VERSION ""

NS_ :

BS_:

BU_: AVM SCC ACU BCW ECS CLU ESC CGW RVM EPB SAS AFS MDPS FR_CMR FR_RDR HUD
VAL_TABLE_ CF_AVN_WarningTimingNValueSet 7 "Invliad" 6 "Reserved" 5 "Reserved" 4 "Reserved" 3 "Reserved" 2 "Normal" 1 "Late" 0 "Default" ;

BO_ 3221225472 VECTOR__INDEPENDENT_SIG_MSG: 0 Vector__XXX
 SG_ ISLA_OptUsmSta : 0|8@1+ (1,0) [0|255] "" Vector__XXX
 SG_ FRM_FORMAT : 0|8@1+ (1,0) [0|31] "" Vector__XXX
 SG_ SID : 0|8@1+ (1,0) [0|255] "" Vector__XXX
 SG_ REQ_RESPONSE : 0|8@1+ (1,0) [0|2] "" Vector__XXX

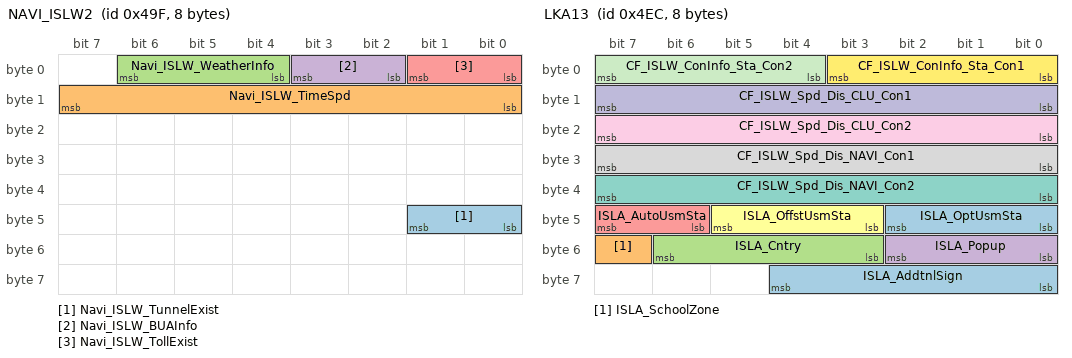
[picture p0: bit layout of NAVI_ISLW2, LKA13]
BO_ 1183 NAVI_ISLW2: 8 CGW
 SG_ Navi_ISLW_TunnelExist : 40|2@1+ (1,0) [0|3] ""  FR_CMR
 SG_ Navi_ISLW_TimeSpd : 8|8@1+ (1,0) [0|255] ""  FR_CMR
 SG_ Navi_ISLW_WeatherInfo : 4|3@1+ (1,0) [0|7] ""  FR_CMR
 SG_ Navi_ISLW_BUAInfo : 2|2@1+ (1,0) [0|3] ""  FR_CMR
 SG_ Navi_ISLW_TollExist : 0|2@1+ (1,0) [0|3] ""  FR_CMR

BO_ 1260 LKA13: 8 FR_CMR
 SG_ ISLA_AddtnlSign : 56|5@1+ (1,0) [0|31] ""  CLU,CGW
 SG_ ISLA_SchoolZone : 55|1@1+ (1,0) [0|1] ""  CLU,CGW
 SG_ ISLA_Cntry : 51|4@1+ (1,0) [0|15] ""  CLU,CGW
 SG_ ISLA_Popup : 48|3@1+ (1,0) [0|7] ""  CLU,CGW
 SG_ ISLA_AutoUsmSta : 46|2@1+ (1,0) [0|3] ""  CLU,CGW
 SG_ ISLA_OffstUsmSta : 43|3@1+ (1,0) [0|7] ""  CLU,CGW
 SG_ CF_ISLW_Spd_Dis_NAVI_Con2 : 32|8@1+ (1,0) [0|255] "" Vector__XXX
 SG_ CF_ISLW_Spd_Dis_NAVI_Con1 : 24|8@1+ (1,0) [-128|127] ""  CGW
 SG_ CF_ISLW_Spd_Dis_CLU_Con2 : 16|8@1+ (1,0) [0|255] "" Vector__XXX
 SG_ CF_ISLW_Spd_Dis_CLU_Con1 : 8|8@1+ (1,0) [0|255] ""  CLU,CGW
 SG_ CF_ISLW_ConInfo_Sta_Con2 : 4|4@1+ (1,0) [0|15] ""  CLU,CGW
 SG_ CF_ISLW_ConInfo_Sta_Con1 : 0|4@1+ (1,0) [0|15] ""  CGW,CLU
 SG_ ISLA_OptUsmSta : 40|3@1+ (1,0) [0|7] ""  SCC,CLU,CGW

BO_ 2679898134 MEAS_5: 8 FR_CMR
 SG_ Meas5Data : 0|64@1+ (1,0) [0|1.84467440737096E+019] "" Vector__XXX

BO_ 2679898133 MEAS_4: 8 FR_CMR
 SG_ Meas4Data : 0|64@1+ (1,0) [0|1.84467440737096E+019] "" Vector__XXX

BO_ 2679898132 MEAS_3: 8 FR_CMR
 SG_ Meas3Data : 0|64@1+ (1,0) [0|1.84467440737096E+019] "" Vector__XXX

BO_ 2679898131 MEAS_2: 8 FR_CMR
 SG_ Meas2Data : 0|64@1+ (1,0) [0|1.84467440737096E+019] "" Vector__XXX

BO_ 2679898130 MEAS_1: 8 FR_CMR
 SG_ Meas1Data : 0|64@1+ (1,0) [0|0] "" Vector__XXX

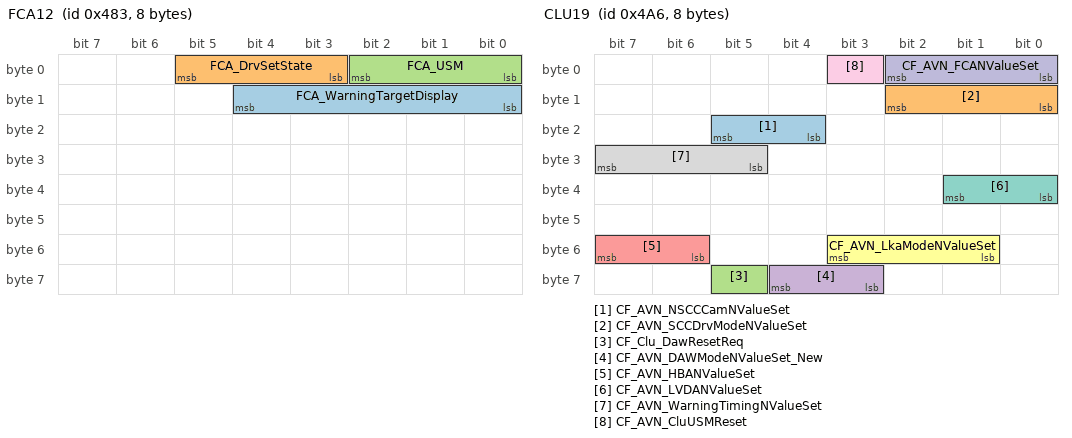
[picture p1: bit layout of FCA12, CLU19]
BO_ 1155 FCA12: 8 FR_CMR
 SG_ FCA_WarningTargetDisplay : 8|5@1+ (1,0) [0|31] ""  CLU
 SG_ FCA_DrvSetState : 3|3@1+ (1,0) [0|7] ""  FR_CMR,CLU
 SG_ FCA_USM : 0|3@1+ (1,0) [0|7] ""  ESC,CLU

BO_ 1190 CLU19: 8 CLU
 SG_ CF_AVN_NSCCCamNValueSet : 20|2@1+ (1,0) [0|3] ""  SCC,FR_CMR
 SG_ CF_AVN_SCCDrvModeNValueSet : 8|3@1+ (1,0) [0|7] ""  SCC,FR_CMR
 SG_ CF_Clu_DawResetReq : 61|1@1+ (1,0) [0|1] ""  FR_CMR
 SG_ CF_AVN_DAWModeNValueSet_New : 59|2@1+ (1,0) [0|3] "" Vector__XXX
 SG_ CF_AVN_HBANValueSet : 54|2@1+ (1,0) [0|3] ""  FR_CMR
 SG_ CF_AVN_LkaModeNValueSet : 49|3@1+ (1,0) [0|7] ""  FR_CMR
 SG_ CF_AVN_LVDANValueSet : 32|2@1+ (1,0) [0|3] ""  FR_CMR
 SG_ CF_AVN_WarningTimingNValueSet : 29|3@1+ (1,0) [0|7] ""  FR_CMR
 SG_ CF_AVN_CluUSMReset : 3|1@1+ (1,0) [0|1] ""  FR_CMR
 SG_ CF_AVN_FCANValueSet : 0|3@1+ (1,0) [0|7] ""  FR_CMR

BO_ 1729 XCP_Tx_Pdu: 8 FR_CMR
 SG_ XCP_Tx_Data : 0|64@1+ (1,0) [0|1.84467440737096E+019] "" Vector__XXX

BO_ 1728 XCP_Rx_Pdu: 8 Vector__XXX
 SG_ XCP_Rx_Data : 0|64@1+ (1,0) [0|1.84467440737096E+019] ""  FR_CMR

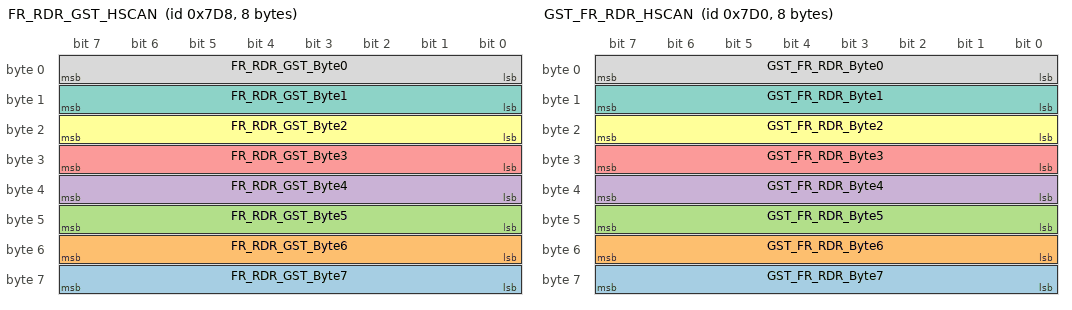
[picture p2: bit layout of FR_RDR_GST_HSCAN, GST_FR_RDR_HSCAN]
BO_ 2008 FR_RDR_GST_HSCAN: 8 FR_CMR
 SG_ FR_RDR_GST_Byte7 : 56|8@1+ (1,0) [0|255] ""  CGW
 SG_ FR_RDR_GST_Byte6 : 48|8@1+ (1,0) [0|255] ""  CGW
 SG_ FR_RDR_GST_Byte5 : 40|8@1+ (1,0) [0|255] ""  CGW
 SG_ FR_RDR_GST_Byte4 : 32|8@1+ (1,0) [0|255] ""  CGW
 SG_ FR_RDR_GST_Byte3 : 24|8@1+ (1,0) [0|255] ""  CGW
 SG_ FR_RDR_GST_Byte2 : 16|8@1+ (1,0) [0|255] ""  CGW
 SG_ FR_RDR_GST_Byte1 : 8|8@1+ (1,0) [0|255] ""  CGW
 SG_ FR_RDR_GST_Byte0 : 0|8@1+ (1,0) [0|255] ""  CGW

BO_ 2000 GST_FR_RDR_HSCAN: 8 CGW
 SG_ GST_FR_RDR_Byte7 : 56|8@1+ (1,0) [0|255] ""  FR_CMR
 SG_ GST_FR_RDR_Byte6 : 48|8@1+ (1,0) [0|255] ""  FR_CMR
 SG_ GST_FR_RDR_Byte5 : 40|8@1+ (1,0) [0|255] ""  FR_CMR
 SG_ GST_FR_RDR_Byte4 : 32|8@1+ (1,0) [0|255] ""  FR_CMR
 SG_ GST_FR_RDR_Byte3 : 24|8@1+ (1,0) [0|255] ""  FR_CMR
 SG_ GST_FR_RDR_Byte2 : 16|8@1+ (1,0) [0|255] ""  FR_CMR
 SG_ GST_FR_RDR_Byte1 : 8|8@1+ (1,0) [0|255] ""  FR_CMR
 SG_ GST_FR_RDR_Byte0 : 0|8@1+ (1,0) [0|255] ""  FR_CMR

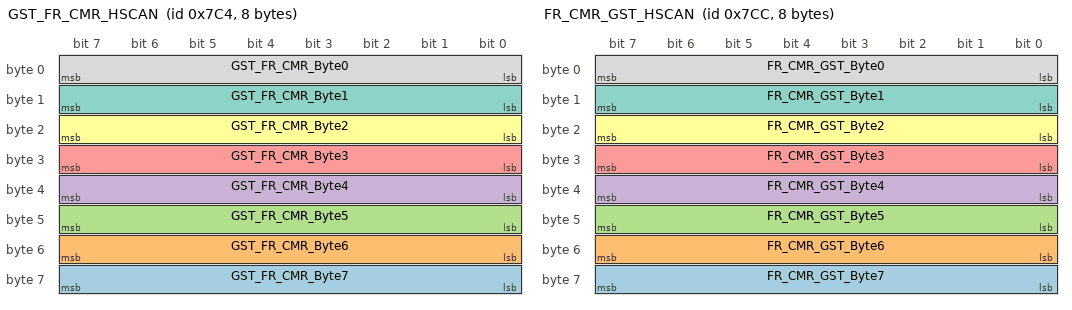
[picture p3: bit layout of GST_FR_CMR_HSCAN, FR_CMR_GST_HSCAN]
BO_ 1988 GST_FR_CMR_HSCAN: 8 CGW
 SG_ GST_FR_CMR_Byte7 : 56|8@1+ (1,0) [0|255] ""  FR_CMR
 SG_ GST_FR_CMR_Byte6 : 48|8@1+ (1,0) [0|255] ""  FR_CMR
 SG_ GST_FR_CMR_Byte5 : 40|8@1+ (1,0) [0|255] ""  FR_CMR
 SG_ GST_FR_CMR_Byte4 : 32|8@1+ (1,0) [0|255] ""  FR_CMR
 SG_ GST_FR_CMR_Byte3 : 24|8@1+ (1,0) [0|255] ""  FR_CMR
 SG_ GST_FR_CMR_Byte2 : 16|8@1+ (1,0) [0|255] ""  FR_CMR
 SG_ GST_FR_CMR_Byte1 : 8|8@1+ (1,0) [0|255] ""  FR_CMR
 SG_ GST_FR_CMR_Byte0 : 0|8@1+ (1,0) [0|255] ""  FR_CMR

BO_ 1996 FR_CMR_GST_HSCAN: 8 FR_CMR
 SG_ FR_CMR_GST_Byte7 : 56|8@1+ (1,0) [0|255] ""  CGW
 SG_ FR_CMR_GST_Byte6 : 48|8@1+ (1,0) [0|255] ""  CGW
 SG_ FR_CMR_GST_Byte5 : 40|8@1+ (1,0) [0|255] ""  CGW
 SG_ FR_CMR_GST_Byte4 : 32|8@1+ (1,0) [0|255] ""  CGW
 SG_ FR_CMR_GST_Byte3 : 24|8@1+ (1,0) [0|255] ""  CGW
 SG_ FR_CMR_GST_Byte2 : 16|8@1+ (1,0) [0|255] ""  CGW
 SG_ FR_CMR_GST_Byte1 : 8|8@1+ (1,0) [0|255] ""  CGW
 SG_ FR_CMR_GST_Byte0 : 0|8@1+ (1,0) [0|255] ""  CGW

BO_ 550 NAVI_STD_STUB_E: 8 CGW
 SG_ STUB_MessageType : 0|3@1+ (1,0) [0|7] ""  FR_CMR,SCC
 SG_ STUB_Offset : 3|13@1+ (1,0) [0|8191] ""  FR_CMR,SCC
 SG_ STUB_CyclicCounter : 16|2@1+ (1,0) [0|3] ""  FR_CMR,SCC
 SG_ STUB_PathIndex : 18|6@1+ (1,0) [0|63] ""  FR_CMR,SCC
 SG_ STUB_SubPathIndex : 24|6@1+ (1,0) [0|63] ""  FR_CMR,SCC
 SG_ STUB_Retransmission : 30|1@1+ (1,0) [0|1] ""  FR_CMR,SCC
 SG_ STUB_Update : 31|1@1+ (1,0) [0|1] ""  FR_CMR,SCC
 SG_ STUB_RelativeProbability : 32|5@1+ (3.333,0) [0|103.323] ""  FR_CMR,SCC
 SG_ STUB_FunctionalRoadClass : 37|3@1+ (1,0) [0|7] ""  FR_CMR,SCC
 SG_ STUB_CalculatedRoute : 40|2@1+ (1,0) [0|3] ""  FR_CMR,SCC
 SG_ STUB_ComplexIntersection : 42|2@1+ (1,0) [0|3] ""  FR_CMR,SCC
 SG_ STUB_FormOfWay : 44|4@1+ (1,0) [0|15] ""  FR_CMR,SCC
 SG_ STUB_TurnAngle : 48|8@1+ (1.417,0) [0|361.335] ""  FR_CMR,SCC
 SG_ STUB_LastStubAtOffset : 56|1@1+ (1,0) [0|1] ""  FR_CMR,SCC
 SG_ STUB_RightOfWay : 57|2@1+ (1,0) [0|3] ""  FR_CMR,SCC
 SG_ STUB_OppositeLanes : 59|2@1+ (1,0) [0|3] ""  FR_CMR,SCC
 SG_ STUB_DirectionLanes : 61|3@1+ (1,0) [0|7] ""  FR_CMR,SCC

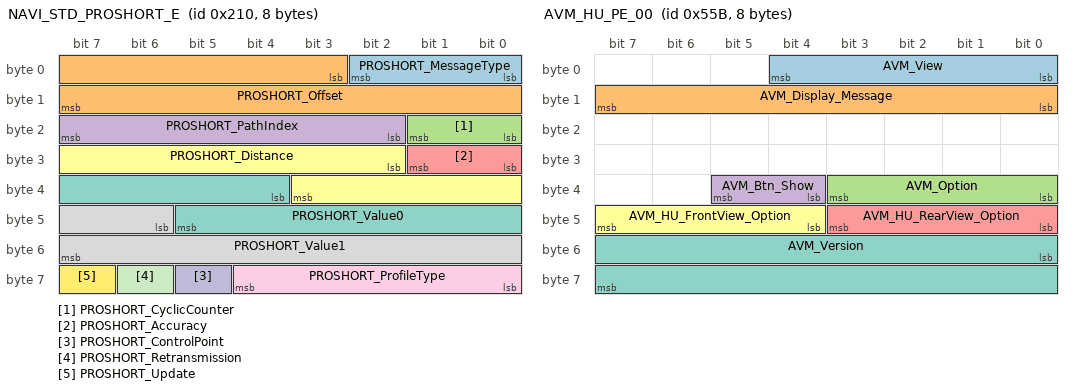
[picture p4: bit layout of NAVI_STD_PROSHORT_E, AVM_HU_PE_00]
BO_ 528 NAVI_STD_PROSHORT_E: 8 CGW
 SG_ PROSHORT_MessageType : 0|3@1+ (1,0) [0|7] ""  FR_CMR,SCC
 SG_ PROSHORT_Offset : 3|13@1+ (1,0) [0|8191] ""  FR_CMR,SCC
 SG_ PROSHORT_CyclicCounter : 16|2@1+ (1,0) [0|3] ""  FR_CMR,SCC
 SG_ PROSHORT_PathIndex : 18|6@1+ (1,0) [0|63] ""  FR_CMR,SCC
 SG_ PROSHORT_Accuracy : 24|2@1+ (1,0) [0|3] ""  FR_CMR,SCC
 SG_ PROSHORT_Distance : 26|10@1+ (1,0) [0|1023] ""  FR_CMR,SCC
 SG_ PROSHORT_Value0 : 36|10@1+ (1,0) [0|1023] ""  FR_CMR,SCC
 SG_ PROSHORT_Value1 : 46|10@1+ (1,0) [0|1023] ""  FR_CMR,SCC
 SG_ PROSHORT_ProfileType : 56|5@1+ (1,0) [0|31] ""  FR_CMR,SCC
 SG_ PROSHORT_ControlPoint : 61|1@1+ (1,0) [0|1] ""  FR_CMR,SCC
 SG_ PROSHORT_Retransmission : 62|1@1+ (1,0) [0|1] ""  FR_CMR,SCC
 SG_ PROSHORT_Update : 63|1@1+ (1,0) [0|1] ""  FR_CMR,SCC

BO_ 524 NAVI_STD_SEG_E: 8 CGW
 SG_ SEG_MessageType : 0|3@1+ (1,0) [0|7] ""  FR_CMR,SCC
 SG_ SEG_Offset : 3|13@1+ (1,0) [0|8191] ""  FR_CMR,SCC
 SG_ SEG_CyclicCounter : 16|2@1+ (1,0) [0|3] ""  FR_CMR,SCC
 SG_ SEG_PathIndex : 18|6@1+ (1,0) [0|63] ""  FR_CMR,SCC
 SG_ SEG_Tunnel : 24|2@1+ (1,0) [0|3] ""  FR_CMR,SCC
 SG_ SEG_Bridge : 26|2@1+ (1,0) [0|3] ""  FR_CMR,SCC
 SG_ SEG_BuiltUpArea : 28|2@1+ (1,0) [0|3] ""  FR_CMR,SCC
 SG_ SEG_Retransmission : 30|1@1+ (1,0) [0|1] ""  FR_CMR,SCC
 SG_ SEG_Update : 31|1@1+ (1,0) [0|1] ""  FR_CMR,SCC
 SG_ SEG_RelativeProbability : 32|5@1+ (3.333,0) [0|103.323] ""  FR_CMR,SCC
 SG_ SEG_FunctionalRoadClass : 37|3@1+ (1,0) [0|7] ""  FR_CMR,SCC
 SG_ SEG_CalculatedRoute : 40|2@1+ (1,0) [0|3] ""  FR_CMR,SCC
 SG_ SEG_ComplexIntersection : 42|2@1+ (1,0) [0|3] ""  FR_CMR,SCC
 SG_ SEG_FormOfWay : 44|4@1+ (1,0) [0|15] ""  FR_CMR,SCC
 SG_ SEG_SpeedLimit : 48|5@1+ (1,0) [0|31] ""  FR_CMR,SCC
 SG_ SEG_SpeedLimitType : 53|3@1+ (1,0) [0|7] ""  FR_CMR,SCC
 SG_ SEG_DividedRoad : 57|2@1+ (1,0) [0|3] ""  FR_CMR,SCC
 SG_ SEG_OppositeLanes : 59|2@1+ (1,0) [0|3] ""  FR_CMR,SCC
 SG_ SEG_DirectionLanes : 61|3@1+ (1,0) [0|7] ""  FR_CMR,SCC

BO_ 1371 AVM_HU_PE_00: 8 AVM
 SG_ AVM_View : 0|5@1+ (1,0) [0|31] ""  CGW
 SG_ AVM_Display_Message : 8|8@1+ (1,0) [0|255] ""  CGW
 SG_ AVM_Option : 32|4@1+ (1,0) [0|15] ""  CGW
 SG_ AVM_Btn_Show : 36|2@1+ (1,0) [0|3] "enum"  CGW
 SG_ AVM_HU_RearView_Option : 40|4@1+ (1,0) [0|15] ""  CGW
 SG_ AVM_HU_FrontView_Option : 44|4@1+ (1,0) [0|15] ""  CGW
 SG_ AVM_Version : 48|16@1+ (1,0) [0|65535] ""  CGW

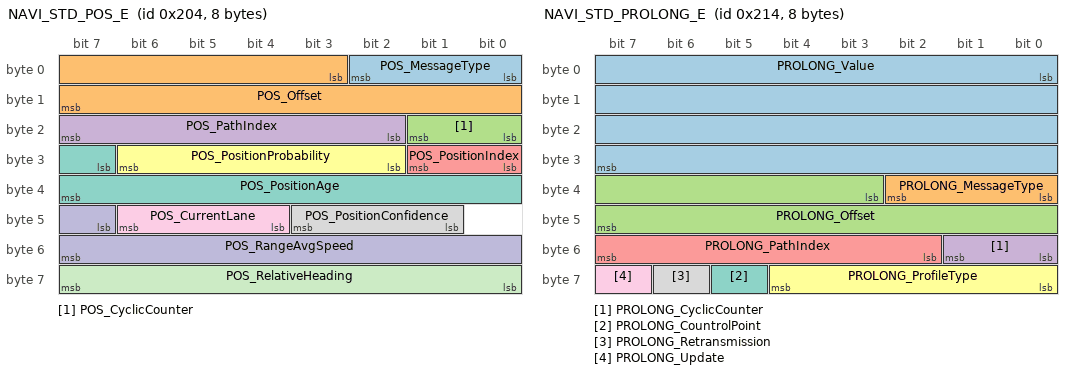
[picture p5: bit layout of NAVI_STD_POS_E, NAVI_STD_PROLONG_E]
BO_ 516 NAVI_STD_POS_E: 8 CGW
 SG_ POS_MessageType : 0|3@1+ (1,0) [0|7] ""  FR_CMR,SCC
 SG_ POS_Offset : 3|13@1+ (1,0) [0|8191] ""  FR_CMR,SCC
 SG_ POS_CyclicCounter : 16|2@1+ (1,0) [0|3] ""  FR_CMR,SCC
 SG_ POS_PathIndex : 18|6@1+ (1,0) [0|63] ""  FR_CMR,SCC
 SG_ POS_PositionIndex : 24|2@1+ (1,0) [0|3] ""  FR_CMR,SCC
 SG_ POS_PositionProbability : 26|5@1+ (3.333,0) [0|103.323] ""  FR_CMR,SCC
 SG_ POS_PositionAge : 31|9@1+ (5,0) [0|2555] ""  FR_CMR,SCC
 SG_ POS_PositionConfidence : 41|3@1+ (1,0) [0|7] ""  FR_CMR,SCC
 SG_ POS_CurrentLane : 44|3@1+ (1,0) [0|7] ""  FR_CMR,SCC
 SG_ POS_RangeAvgSpeed : 47|9@1+ (1,0) [0|511] ""  FR_CMR,SCC
 SG_ POS_RelativeHeading : 56|8@1+ (1.417,0) [0|361.335] ""  FR_CMR,SCC

BO_ 532 NAVI_STD_PROLONG_E: 8 CGW
 SG_ PROLONG_Value : 0|32@1+ (1,0) [0|4294967295] ""  FR_CMR,SCC
 SG_ PROLONG_MessageType : 32|3@1+ (1,0) [0|7] ""  FR_CMR,SCC
 SG_ PROLONG_Offset : 35|13@1+ (1,0) [0|8191] ""  FR_CMR,SCC
 SG_ PROLONG_CyclicCounter : 48|2@1+ (1,0) [0|3] ""  FR_CMR,SCC
 SG_ PROLONG_PathIndex : 50|6@1+ (1,0) [0|63] ""  FR_CMR,SCC
 SG_ PROLONG_ProfileType : 56|5@1+ (1,0) [0|31] ""  FR_CMR,SCC
 SG_ PROLONG_CountrolPoint : 61|1@1+ (1,0) [0|1] ""  FR_CMR,SCC
 SG_ PROLONG_Retransmission : 62|1@1+ (1,0) [0|1] ""  FR_CMR,SCC
 SG_ PROLONG_Update : 63|1@1+ (1,0) [0|1] ""  FR_CMR,SCC

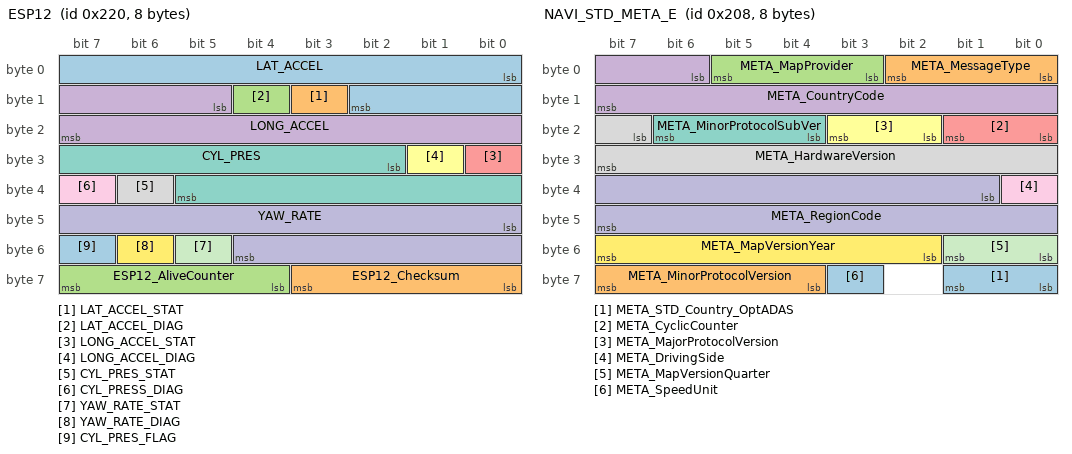
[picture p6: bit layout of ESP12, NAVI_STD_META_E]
BO_ 544 ESP12: 8 ESC
 SG_ LAT_ACCEL : 0|11@1+ (0.01,-10.23) [-10.23|10.24] "m/s^2"  CLU,ECS,FR_RDR,FR_CMR,SCC
 SG_ LAT_ACCEL_STAT : 11|1@1+ (1,0) [0|1] ""  CLU,ECS,FR_RDR,FR_CMR,SCC
 SG_ LAT_ACCEL_DIAG : 12|1@1+ (1,0) [0|1] ""  ECS,FR_RDR,FR_CMR,SCC
 SG_ LONG_ACCEL : 13|11@1+ (0.01,-10.23) [-10.23|10.24] "m/s^2"  CLU,EPB,FR_RDR,FR_CMR,SCC
 SG_ LONG_ACCEL_STAT : 24|1@1+ (1,0) [0|1] ""  CLU,EPB,FR_RDR,FR_CMR,SCC
 SG_ LONG_ACCEL_DIAG : 25|1@1+ (1,0) [0|1] ""  EPB,FR_RDR,FR_CMR,SCC
 SG_ CYL_PRES : 26|12@1+ (0.1,0) [0|409.5] "Bar"  ECS,EPB,FR_RDR,FR_CMR,SCC
 SG_ CYL_PRES_STAT : 38|1@1+ (1,0) [0|1] ""  CGW,ECS,EPB,FR_RDR,FR_CMR,SCC
 SG_ CYL_PRESS_DIAG : 39|1@1+ (1,0) [0|1] ""  ECS,EPB,FR_RDR,FR_CMR,SCC
 SG_ YAW_RATE : 40|13@1+ (0.01,-40.95) [-40.95|40.96] "¢ª/s"  AFS,BCW,FR_RDR,FR_CMR,MDPS,SCC
 SG_ YAW_RATE_STAT : 53|1@1+ (1,0) [0|1] ""  AFS,FR_RDR,FR_CMR,MDPS,SCC
 SG_ YAW_RATE_DIAG : 54|1@1+ (1,0) [0|1] ""  AFS,FR_RDR,FR_CMR,MDPS,SCC
 SG_ CYL_PRES_FLAG : 55|1@1+ (1,0) [0|1] ""  CGW,FR_RDR
 SG_ ESP12_Checksum : 56|4@1+ (1,0) [0|15] ""  ECS,FR_RDR
 SG_ ESP12_AliveCounter : 60|4@1+ (1,0) [0|15] ""  ECS,FR_RDR

BO_ 1369 CGW4: 8 CGW
 SG_ CF_Gway_MemoryP1Cmd : 0|1@1+ (1,0) [0|1] ""  CLU,HUD
 SG_ CF_Gway_MemoryP2Cmd : 1|1@1+ (1,0) [0|1] ""  CLU,HUD
 SG_ CF_Gway_PBackP1Cmd : 2|1@1+ (1,0) [0|1] ""  CLU,HUD
 SG_ CF_Gway_PBackP2Cmd : 3|1@1+ (1,0) [0|1] ""  CLU,HUD
 SG_ CF_Gway_PBackStopCmd : 5|1@1+ (1,0) [0|1] ""  CLU,HUD
 SG_ CF_Gway_DrvWdwStat : 8|1@1+ (1,0) [0|1] ""  CLU
 SG_ CF_Gway_RLWdwState : 9|1@1+ (1,0) [0|1] ""  CLU
 SG_ CF_Gway_RRWdwState : 10|1@1+ (1,0) [0|1] ""  CLU
 SG_ CF_Gway_AstWdwStat : 11|1@1+ (1,0) [0|1] ""  CLU
 SG_ CF_Gway_MemoryEnable : 12|1@1+ (1,0) [0|1] ""  CLU,HUD
 SG_ CF_Gway_IMSBuzzer : 15|1@1+ (1,0) [0|1] ""  CLU
 SG_ C_HSWSSysStat : 16|2@1+ (1,0) [0|3] ""  CLU
 SG_ CF_Gway_WiperSwState : 18|2@1+ (1,0) [0|3] ""  CLU
 SG_ CF_Gway_HCIMSPBackCmd : 20|12@1+ (1,0) [0|4095] ""  HUD
 SG_ CF_Gway_DrvSeatBeltIND : 36|2@1+ (1,0) [0|3] ""  CLU
 SG_ CF_Gway_AstSeatBeltIND : 38|2@1+ (1,0) [0|3] ""  CLU
 SG_ CF_Gway_RCSeatBeltIND : 40|2@1+ (1,0) [0|3] ""  CLU
 SG_ CF_Gway_RLSeatBeltIND : 42|2@1+ (1,0) [0|3] ""  CLU
 SG_ CF_Gway_RRSeatBeltIND : 44|2@1+ (1,0) [0|3] ""  CLU
 SG_ CF_Gway_WPCWarning : 56|3@1+ (1,0) [0|7] ""  CLU
 SG_ CF_Gway_SeatBeltWngBuz : 63|1@1+ (1,0) [0|1] ""  CLU

BO_ 520 NAVI_STD_META_E: 8 CGW
 SG_ META_STD_Country_OptADAS : 56|2@1- (1,0) [-2|1] ""  FR_CMR
 SG_ META_MessageType : 0|3@1+ (1,0) [0|7] ""  FR_CMR,SCC
 SG_ META_MapProvider : 3|3@1+ (1,0) [0|7] ""  FR_CMR,SCC
 SG_ META_CountryCode : 6|10@1+ (1,0) [0|1023] ""  FR_CMR,SCC
 SG_ META_CyclicCounter : 16|2@1+ (1,0) [0|3] ""  FR_CMR,SCC
 SG_ META_MajorProtocolVersion : 18|2@1+ (1,0) [0|3] ""  FR_CMR,SCC
 SG_ META_MinorProtocolSubVer : 20|3@1+ (1,0) [0|7] ""  FR_CMR,SCC
 SG_ META_HardwareVersion : 23|9@1+ (1,0) [0|511] ""  FR_CMR,SCC
 SG_ META_DrivingSide : 32|1@1+ (1,0) [0|1] ""  FR_CMR,SCC
 SG_ META_RegionCode : 33|15@1+ (1,0) [0|32767] ""  FR_CMR,SCC
 SG_ META_MapVersionQuarter : 48|2@1+ (1,0) [0|3] ""  FR_CMR,SCC
 SG_ META_MapVersionYear : 50|6@1+ (1,2000) [2000|2063] ""  FR_CMR,SCC
 SG_ META_SpeedUnit : 59|1@1+ (1,0) [0|1] ""  FR_CMR,SCC
 SG_ META_MinorProtocolVersion : 60|4@1+ (1,0) [0|15] ""  FR_CMR,SCC

BO_ 1363 CGW2: 8 CGW
 SG_ CF_Gway_ExtTailAct : 8|2@1+ (1,0) [0|3] ""  AVM,BCW,CLU,HUD
 SG_ CF_Gway_AutoLightValue : 16|1@1+ (1,0) [0|1] ""  BCW,CLU
 SG_ CF_Gway_BrakeFluidSw : 17|1@1+ (1,0) [0|1] ""  CLU
 SG_ CF_Gway_AvTail : 20|1@1+ (1,0) [0|3] ""  CLU
 SG_ CF_Gway_RearFogAct : 21|1@1+ (1,0) [0|1] ""  CLU
 SG_ CF_Gway_RRDrSw : 23|1@1+ (1,0) [0|1] ""  CLU
 SG_ CF_Gway_RLDrSw : 24|1@1+ (1,0) [0|1] ""  CLU
 SG_ CF_Gway_IntTailAct : 25|1@1+ (1,0) [0|1] ""  CLU
 SG_ CF_Gway_WiperParkPosition : 32|1@1+ (1,0) [0|1] ""  FR_CMR
 SG_ CF_Gway_ESCLNotLockedWarn : 36|1@1+ (1,0) [0|1] ""  CLU
 SG_ CF_Gway_IDoutWarn : 38|1@1+ (1,0) [0|1] ""  CLU
 SG_ CF_Gway_ImmoLp : 40|1@1+ (1,0) [0|3] ""  CLU
 SG_ CF_Gway_VehicleNotPWarn : 44|1@1+ (1,0) [0|1] ""  CLU
 SG_ CF_Gway_DeactivationWarn : 45|1@1+ (1,0) [0|1] ""  CLU
 SG_ CF_Gway_KeyBATDischargeWarn : 46|1@1+ (1,0) [0|1] ""  CLU
 SG_ CF_Gway_SJBDeliveryMode : 55|1@1+ (1,0) [0|1] ""  CLU
 SG_ CF_Gway_SMKDispWarn : 57|4@1+ (1,0) [0|15] ""  CLU
 SG_ CF_Gway_WngBuz : 61|3@1+ (1,0) [0|7] ""  CLU

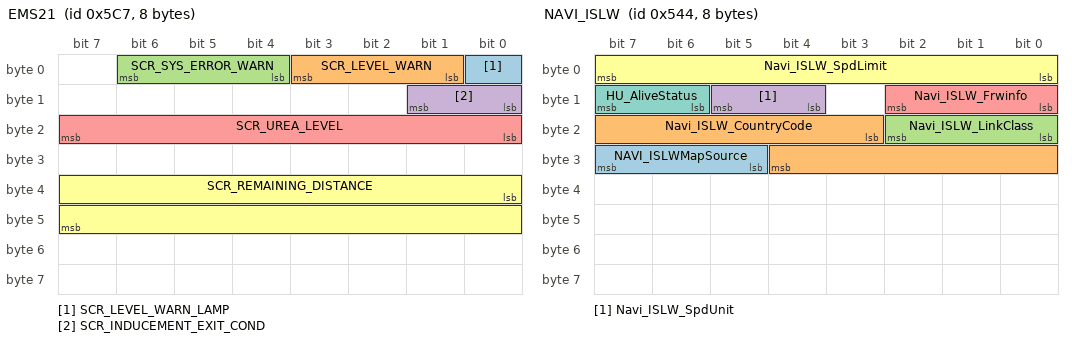
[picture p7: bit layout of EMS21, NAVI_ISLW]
BO_ 1479 EMS21: 8 CGW
 SG_ SCR_LEVEL_WARN_LAMP : 0|1@1+ (1,0) [0|1] ""  CLU
 SG_ SCR_LEVEL_WARN : 1|3@1+ (1,0) [0|4] ""  CLU
 SG_ SCR_SYS_ERROR_WARN : 4|3@1+ (1,0) [0|7] ""  CLU
 SG_ SCR_INDUCEMENT_EXIT_COND : 8|2@1+ (1,0) [0|3] ""  CLU
 SG_ SCR_UREA_LEVEL : 16|8@1+ (0.5,0) [0|100] "%"  CLU
 SG_ SCR_REMAINING_DISTANCE : 32|16@1+ (1,0) [0|25000] "km"  CLU

BO_ 1348 NAVI_ISLW: 8 CGW
 SG_ NAVI_ISLWMapSource : 29|3@1+ (1,0) [0|7] ""  FR_CMR
 SG_ Navi_ISLW_CountryCode : 19|10@1+ (1,0) [0|1023] ""  FR_CMR
 SG_ Navi_ISLW_LinkClass : 16|3@1+ (1,0) [0|7] ""  FR_CMR
 SG_ Navi_ISLW_SpdUnit : 12|2@1+ (1,0) [0|3] "" Vector__XXX
 SG_ Navi_ISLW_Frwinfo : 8|3@1+ (1,0) [0|7] ""  FR_CMR
 SG_ Navi_ISLW_SpdLimit : 0|8@1+ (1,0) [0|255] ""  FR_CMR
 SG_ HU_AliveStatus : 14|2@1+ (1,0) [0|3] ""  FR_CMR,SCC

BO_ 809 EMS12: 8 CGW
 SG_ TQ_STND m3 : 0|6@1+ (10,0) [0|630] "Nm"  CLU,EPB
 SG_ CONF_TCU m1 : 0|6@1+ (1,0) [0|63] ""  BCW,EPB,FR_RDR
 SG_ MUL_CODE M : 6|2@1+ (1,0) [0|3] ""  BCW,CLU,EPB,FR_RDR
 SG_ TEMP_ENG : 8|8@1+ (0.75,-48) [-48|143.25] "¡É"  CLU,EPB
 SG_ ACC_ACT : 30|1@1+ (1,0) [0|1] ""  FR_RDR,FR_CMR
 SG_ BRAKE_ACT : 32|2@1+ (1,0) [0|3] ""  AFS,EPB,FR_CMR
 SG_ ENG_CHR : 34|4@1+ (1,0) [0|15] ""  EPB
 SG_ TPS : 40|8@1+ (0.4694836,-15.0234742) [-15.0234742|104.6948357] "%"  EPB
 SG_ PV_AV_CAN : 48|8@1+ (0.3906,0) [0|99.603] "%"  AFS,ECS,EPB,FR_RDR,FR_CMR,SCC
 SG_ ENG_VOL : 56|8@1+ (0.1,0) [0|25.5] "liter"  EPB

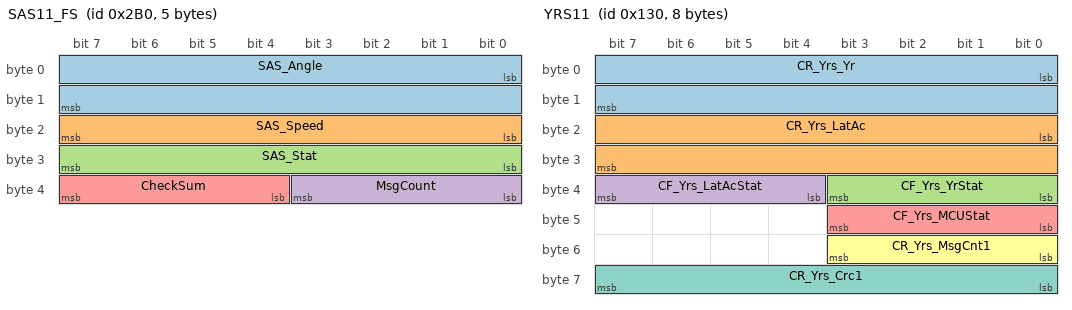
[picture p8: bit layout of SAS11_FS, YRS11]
BO_ 688 SAS11_FS: 5 SAS
 SG_ SAS_Angle : 0|16@1+ (0.1,0) [0|6553.5] "Deg"  AFS,AVM,CGW,ECS,ESC,FR_RDR,FR_CMR,MDPS,RVM,SCC
 SG_ SAS_Speed : 16|8@1+ (4,0) [0|1020] ""  AFS,CGW,ECS,ESC,FR_RDR,FR_CMR,MDPS,SCC
 SG_ SAS_Stat : 24|8@1+ (1,0) [0|255] ""  CGW,ECS,ESC,FR_RDR,FR_CMR,MDPS,SCC
 SG_ MsgCount : 32|4@1+ (1,0) [0|15] ""  CGW,ECS,ESC,FR_RDR,FR_CMR,MDPS,SCC
 SG_ CheckSum : 36|4@1+ (1,0) [0|15] ""  CGW,ECS,ESC,FR_RDR,FR_CMR,MDPS,SCC

BO_ 1107 CGW_PC1: 5 CGW
 SG_ CR_Fatc_OutTempSns : 16|8@1+ (0.5,-40) [-40|60] "¡É"  CLU

BO_ 1345 CGW1: 8 CGW
 SG_ CF_Gway_IGNSw : 0|3@1+ (1,0) [0|7] ""  SCC,BCW,AVM,CLU,EPB,HUD,RVM
 SG_ CF_Gway_RKECmd : 3|3@1+ (1,0) [0|7] ""  CLU
 SG_ CF_Gway_DrvDrSw : 8|2@1+ (1,0) [0|3] ""  CLU,EPB,FR_CMR,SCC
 SG_ CF_Gway_DrvSeatBeltSw : 10|2@1+ (1,0) [0|3] ""  EPB,FR_CMR
 SG_ CF_Gway_TrunkTgSw : 12|2@1+ (1,0) [0|3] ""  CLU,EPB
 SG_ CF_Gway_SMKOption : 16|1@1+ (1,0) [0|1] ""  CLU
 SG_ CF_Gway_HoodSw : 17|2@1+ (1,0) [0|3] ""  CLU,EPB
 SG_ CF_Gway_TurnSigLh : 19|2@1+ (1,0) [0|3] ""  BCW,CLU,FR_CMR,SCC
 SG_ CF_Gway_WiperIntT : 21|3@1+ (1,0) [0|7] ""  CLU,FR_CMR
 SG_ CF_Gway_WiperIntSw : 24|1@1+ (1,0) [0|1] ""  FR_CMR
 SG_ CF_Gway_WiperLowSw : 25|1@1+ (1,0) [0|1] ""  FR_CMR
 SG_ CF_Gway_WiperHighSw : 26|1@1+ (1,0) [0|1] ""  FR_CMR
 SG_ CF_Gway_WiperAutoSw : 27|1@1+ (1,0) [0|1] ""  FR_CMR
 SG_ CF_Gway_HeadLampLow : 31|1@1+ (1,0) [0|1] ""  AFS,CLU,FR_CMR
 SG_ CF_Gway_HeadLampHigh : 32|1@1+ (1,0) [0|1] ""  AFS,CLU,FR_CMR
 SG_ CF_Gway_HazardSw : 33|2@1+ (1,0) [0|3] ""  FR_CMR
 SG_ CF_Gway_AstDrSw : 35|1@1+ (1,0) [0|1] ""  CLU
 SG_ CF_Gway_LightSwState : 38|2@1+ (1,0) [0|3] ""  FR_CMR,AFS,CLU
 SG_ CF_Gway_TSigRHSw : 41|1@1+ (1,0) [0|1] ""  FR_CMR
 SG_ CF_Gway_TSigLHSw : 42|1@1+ (1,0) [0|1] ""  FR_CMR
 SG_ CF_Gway_DriveTypeOption : 43|1@1+ (1,0) [0|1] ""  CLU
 SG_ CF_Gway_PassiveAccessLock : 45|2@1+ (1,0) [0|7] ""  CLU
 SG_ CF_Gway_PassiveAccessUnlock : 48|2@1+ (1,0) [0|7] ""  CLU
 SG_ CF_Gway_PassingSW : 51|1@1+ (1,0) [0|1] ""  FR_CMR,AFS
 SG_ CF_Gway_HBAControlMode : 52|1@1+ (1,0) [0|1] ""  FR_CMR
 SG_ CF_Gway_InhibitRMT : 54|2@1+ (1,0) [0|3] ""  AFS,BCW,CLU,FR_RDR,FR_CMR
 SG_ CF_Gway_RainSnsOption : 56|1@1+ (1,0) [0|1] ""  CLU
 SG_ C_SunRoofOpenState : 57|1@1+ (1,0) [0|1] ""  CLU
 SG_ CF_Gway_ParkBrakeSw : 60|2@1+ (1,0) [0|3] ""  CLU
 SG_ CF_Gway_TurnSigRh : 62|2@1+ (1,0) [0|3] ""  BCW,CLU,FR_CMR,SCC

BO_ 304 YRS11: 8 ACU
 SG_ CR_Yrs_Yr : 0|16@1+ (0.005,-163.84) [-163.84|163.83] "¢ª/s"  ESC
 SG_ CR_Yrs_LatAc : 16|16@1+ (0.000127465,-4.17677312) [-4.17677312|4.17651819] "g"  ESC
 SG_ CF_Yrs_YrStat : 32|4@1+ (1,0) [0|15] ""  ESC
 SG_ CF_Yrs_LatAcStat : 36|4@1+ (1,0) [0|15] ""  ESC
 SG_ CF_Yrs_MCUStat : 40|4@1+ (1,0) [0|15] ""  ESC
 SG_ CR_Yrs_MsgCnt1 : 48|4@1+ (1,0) [0|15] ""  ESC
 SG_ CR_Yrs_Crc1 : 56|8@1+ (1,0) [0|255] ""  ESC

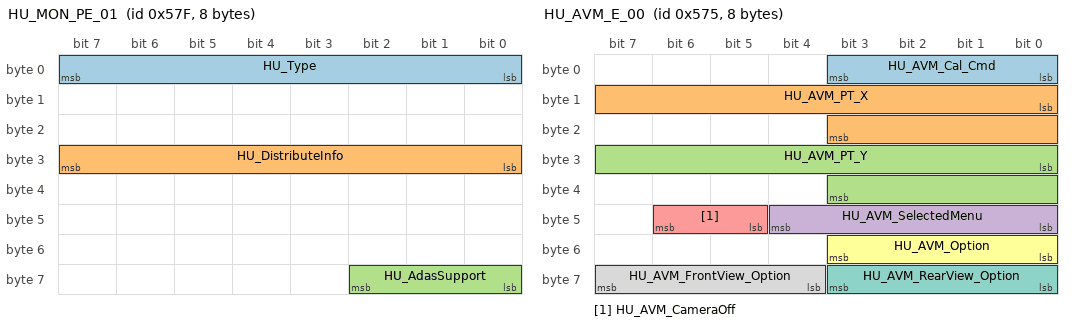
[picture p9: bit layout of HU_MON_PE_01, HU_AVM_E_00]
BO_ 1407 HU_MON_PE_01: 8 CGW
 SG_ HU_Type : 0|8@1+ (1,0) [0|255] ""  AVM,FR_CMR,RVM
 SG_ HU_DistributeInfo : 24|8@1+ (1,0) [0|255] ""  FR_CMR,SCC
 SG_ HU_AdasSupport : 56|3@1+ (1,0) [0|7] ""  FR_CMR,SCC

BO_ 1397 HU_AVM_E_00: 8 CGW
 SG_ HU_AVM_Cal_Cmd : 0|4@1+ (1,0) [0|15] ""  AVM
 SG_ HU_AVM_PT_X : 8|12@1+ (1,0) [0|4095] ""  AVM
 SG_ HU_AVM_PT_Y : 24|12@1+ (1,0) [0|4095] ""  AVM
 SG_ HU_AVM_SelectedMenu : 40|5@1+ (1,0) [0|31] ""  AVM
 SG_ HU_AVM_CameraOff : 45|2@1+ (1,0) [0|3] ""  AVM
 SG_ HU_AVM_Option : 48|4@1+ (1,0) [0|15] ""  AVM
 SG_ HU_AVM_RearView_Option : 56|4@1+ (1,0) [0|15] ""  AVM
 SG_ HU_AVM_FrontView_Option : 60|4@1+ (1,0) [0|15] ""  AVM

CM_ BO_ 3221225472 "This is a message for not used signals, created by Vector CANdb++ DBC OLE DB Provider.";
CM_ SG_ 3221225472 ISLA_OptUsmSta "This is a ISLA Option USM signal set by the driver.";
CM_ SG_ 3221225472 FRM_FORMAT "If the value of this signal is not 2H, this signal can be ignored.*)
*) If an ECU has diagnostic communication on CAN service functionallty and communicate with an tester via CAN then must consider other message format. (DO NOT IGNORE OTHER CASES!)";
CM_ SG_ 1183 Navi_ISLW_TunnelExist "TomTom Weather information for MFC";
CM_ SG_ 1183 Navi_ISLW_TimeSpd "BUA entrance/exit information for MFC";
CM_ SG_ 1183 Navi_ISLW_WeatherInfo "Time restricted speed limit information on the road for MFC";
CM_ SG_ 1183 Navi_ISLW_BUAInfo "Tunnel existence information for MFC";
CM_ SG_ 1183 Navi_ISLW_TollExist "Toll exist information to MFC";
CM_ SG_ 1260 ISLA_AddtnlSign "This is a signal for additional sign";
CM_ SG_ 1260 ISLA_SchoolZone "This is a signal for School Zone";
CM_ SG_ 1260 ISLA_Cntry "This is a signal for categorizing countries";
CM_ SG_ 1260 ISLA_Popup "This is a signal for ISLA pop-up.";
CM_ SG_ 1260 ISLA_AutoUsmSta "This is a signal for ISLA AUTO USM set by the driver.";
CM_ SG_ 1260 ISLA_OffstUsmSta "This is a signal for offset speed set by the driver.
Unit (kph or mph) refers to cluster signal : CF_Clu_SPEED_UNIT@CLU11";
CM_ SG_ 1260 CF_ISLW_Spd_Dis_NAVI_Con2 "Indicates speed limit of 2nd conditional traffic sign

0x0:No Recognition (Default)

0x1~0xFC:1~252 (PH)=1*(HEX)

0xFD:LHD Conditional No Passing ZONE

0xFE:RHD Conditional No Passing ZONE

0xFF:Invalid";
CM_ SG_ 1260 CF_ISLW_Spd_Dis_NAVI_Con1 "Indicates speed limit of 1st conditional traffic sign

0x0:No Recognition (Default)

0x1~0xFC:1~252 (PH)=1*(HEX)

0xFD:LHD Conditional No Passing ZONE

0xFE:RHD Conditional No Passing ZONE

0xFF:Invalid";
CM_ SG_ 1260 CF_ISLW_Spd_Dis_CLU_Con2 "Indicates speed limit of 2nd conditional traffic sign

0x0:No Recognition (Default)

0x1~0xFC:1~252 (PH)=1*(HEX)

0xFD:LHD Conditional No Passing ZONE

0xFE:RHD Conditional No Passing ZONE

0xFF:Invalid";
CM_ SG_ 1260 CF_ISLW_Spd_Dis_CLU_Con1 "Indicates speed limit of 1st conditional traffic sign

0x0:No Recognition (Default)

0x1~0xFC:1~252 (PH)=1*(HEX)

0xFD:LHD Conditional No Passing ZONE

0xFE:RHD Conditional No Passing ZONE

0xFF:Invalid";
CM_ SG_ 1260 CF_ISLW_ConInfo_Sta_Con2 "Indicates 2nd conditional traffic sign status";
CM_ SG_ 1260 CF_ISLW_ConInfo_Sta_Con1 "Indicates 1st conditional traffic sign status";
CM_ SG_ 1260 ISLA_OptUsmSta "This is a ISLA Option USM signal set by the driver.";
CM_ BO_ 2679898134 "[P] Periodic";
CM_ BO_ 2679898133 "[P] Periodic";
CM_ BO_ 2679898132 "[P] Periodic";
CM_ BO_ 2679898131 "[P] Periodic";
CM_ BO_ 2679898130 "[P] Periodic";
CM_ BO_ 1729 "[PE] Periodic and On Event";
CM_ SG_ 1729 XCP_Tx_Data "XCP DTO Message Signal";
CM_ BO_ 1728 "[E] On Event";
CM_ SG_ 1728 XCP_Rx_Data "XCP CTO Message Signal";
CM_ BO_ 2008 "[E] On Event";
CM_ BO_ 2000 "[E] On Event";
CM_ BO_ 1988 "[E] On Event";
CM_ BO_ 1996 "[E] On Event";
CM_ BO_ 550 "[E] On Event";
CM_ SG_ 550 STUB_MessageType "This is Stub Message for Map Based ADAS.";
CM_ SG_ 550 STUB_Offset "This is Stub Offset for Map Based ADAS.";
CM_ SG_ 550 STUB_CyclicCounter "This is Stub Cyclic Counter for Map Based ADAS.";
CM_ SG_ 550 STUB_PathIndex "This is Stub Message for Map Based ADAS.";
CM_ SG_ 550 STUB_SubPathIndex "This is Stub Sub Path Index for Map Based ADAS.";
CM_ SG_ 550 STUB_Retransmission "This is Stub Retransmission Flag for Map Based ADAS.";
CM_ SG_ 550 STUB_Update "This is Stub Update Flag for Map Based ADAS.";
CM_ SG_ 550 STUB_RelativeProbability "This is Stub Message for Map Based ADAS.";
CM_ SG_ 550 STUB_FunctionalRoadClass "This is Stub Functional Road Class for Map Based ADAS.";
CM_ SG_ 550 STUB_CalculatedRoute "This is Stub Calculated Route state for Map Based ADAS.";
CM_ SG_ 550 STUB_ComplexIntersection "This is Stub Complex Intersection Information for Map Based ADAS.";
CM_ SG_ 550 STUB_FormOfWay "This is Stub Form of Way for Map Based ADAS.";
CM_ SG_ 550 STUB_TurnAngle "This is Stub Turn Angle for Map Based ADAS.";
CM_ SG_ 550 STUB_LastStubAtOffset "This is Last Stub at Offset for Map Based ADAS.";
CM_ SG_ 550 STUB_RightOfWay "This is Stub Right of Way Information for Map Based ADAS.";
CM_ SG_ 550 STUB_OppositeLanes "This is number of Stub Opposite Lanes for Map Based ADAS.";
CM_ SG_ 550 STUB_DirectionLanes "This is number of Stub Direction Lanes for Map Based ADAS.";
CM_ BO_ 528 "[E] On Event";
CM_ SG_ 528 PROSHORT_MessageType "This is Profile Short Message Type for Map Based ADAS.";
CM_ SG_ 528 PROSHORT_Offset "This is Profile Short Offset for Map Based ADAS.";
CM_ SG_ 528 PROSHORT_CyclicCounter "This is Profile Short Cyclic Counter for Map Based ADAS.";
CM_ SG_ 528 PROSHORT_PathIndex "This is Profile Short Path Index for Map Based ADAS.";
CM_ SG_ 528 PROSHORT_Accuracy "This is Profile Short Accuracy for Map Based ADAS.";
CM_ SG_ 528 PROSHORT_Distance "This is Profile Short Distance for Map Based ADAS.";
CM_ SG_ 528 PROSHORT_Value0 "This is Profile Short Value at Offset for Map Based ADAS.";
CM_ SG_ 528 PROSHORT_Value1 "This is Profile Short Value at Offset+Distance1 for Map Based ADAS.";
CM_ SG_ 528 PROSHORT_ProfileType "This is Profile Short Type for Map Based ADAS.";
CM_ SG_ 528 PROSHORT_ControlPoint "This is Profile Short Control Point Flag for Map Based ADAS.";
CM_ SG_ 528 PROSHORT_Retransmission "This is Profile Short Retransmission Flag for Map Based ADAS.";
CM_ SG_ 528 PROSHORT_Update "This is Profile Short Update Flag for Map Based ADAS.";
CM_ BO_ 524 "[E] On Event";
CM_ SG_ 524 SEG_MessageType "This is Segment Message Type for Map Based ADAS.";
CM_ SG_ 524 SEG_Offset "This is Segment Offset for Map Based ADAS.";
CM_ SG_ 524 SEG_CyclicCounter "This is Segment Cyclic Counter for Map Based ADAS.";
CM_ SG_ 524 SEG_PathIndex "This is Segment Path Index for Map Based ADAS.";
CM_ SG_ 524 SEG_Tunnel "This is Segment Tunnel Information for Map Based ADAS.";
CM_ SG_ 524 SEG_Bridge "This is Segment Message for Map Based ADAS.";
CM_ SG_ 524 SEG_BuiltUpArea "This is Segment Built up Area Information for Map Based ADAS.";
CM_ SG_ 524 SEG_Retransmission "This is Segment Retransmission Flag for Map Based ADAS.";
CM_ SG_ 524 SEG_Update "This is Segment Update Flag for Map Based ADAS.";
CM_ SG_ 524 SEG_RelativeProbability "This is Segment Relative Probability for Map Based ADAS.";
CM_ SG_ 524 SEG_FunctionalRoadClass "This is Segment Road Class for Map Based ADAS.";
CM_ SG_ 524 SEG_CalculatedRoute "This is Segment Calculated Route state for Map Based ADAS.";
CM_ SG_ 524 SEG_ComplexIntersection "This is Segment Complex Intersection Information for Map Based ADAS.";
CM_ SG_ 524 SEG_FormOfWay "This is Segment Link Class for Map Based ADAS.";
CM_ SG_ 524 SEG_SpeedLimit "This is Segment Effective Speed Limit for Map Based ADAS.";
CM_ SG_ 524 SEG_SpeedLimitType "This is Segment Effective Speed Limit Type for Map Based ADAS.";
CM_ SG_ 524 SEG_DividedRoad "This is Segment Divided Road Information For Map Based ADAS.";
CM_ SG_ 524 SEG_OppositeLanes "This is Number of Segment Opposite Lanes for Map Based ADAS.";
CM_ SG_ 524 SEG_DirectionLanes "This is Number of Segment Direction Lanes for Map Based ADAS.";
CM_ BO_ 1371 "[PE] Periodic and On Event";
CM_ BO_ 516 "[E] On Event";
CM_ SG_ 516 POS_MessageType "This is Position Message Type for Map Based ADAS.";
CM_ SG_ 516 POS_Offset "This is Position Offset for Map Based ADAS.";
CM_ SG_ 516 POS_CyclicCounter "This is Cyclic Counter for Map Based ADAS.";
CM_ SG_ 516 POS_PathIndex "This is Position Path Index for Map Based ADAS.";
CM_ SG_ 516 POS_PositionIndex "This is Position Index for Map Based ADAS.";
CM_ SG_ 516 POS_PositionProbability "This is Position Probility for Map Based ADAS.";
CM_ SG_ 516 POS_PositionAge "This is Position transmission age for Map Based ADAS.";
CM_ SG_ 516 POS_PositionConfidence "This is Position Confidence for Map Based ADAS.";
CM_ SG_ 516 POS_CurrentLane "This is Current Lane for Map Based ADAS.";
CM_ SG_ 516 POS_RangeAvgSpeed "This is range camera average speed for Map Based ADAS.";
CM_ SG_ 516 POS_RelativeHeading "This is relative heading for Map Based ADAS.";
CM_ BO_ 532 "[E] On Event";
CM_ SG_ 532 PROLONG_Value "This is Profile Long Value for Map Based ADAS.";
CM_ SG_ 532 PROLONG_MessageType "This is Profile Long MessageType for Map Based ADAS.";
CM_ SG_ 532 PROLONG_Offset "This is Profile Long Offset for Map Based ADAS.";
CM_ SG_ 532 PROLONG_CyclicCounter "This is Profile Long Cyclic Counter for Map Based ADAS.";
CM_ SG_ 532 PROLONG_PathIndex "This is Profile Long Path Index for Map Based ADAS.";
CM_ SG_ 532 PROLONG_ProfileType "This is Profile Long Type for Map Based ADAS.";
CM_ SG_ 532 PROLONG_CountrolPoint "This is Profile Long Control Point for Map Based ADAS.";
CM_ SG_ 532 PROLONG_Retransmission "This is Profile Long Retransmission Flag for Map Based ADAS.";
CM_ SG_ 532 PROLONG_Update "This is Profile Long Update flag for Map Based ADAS.";
CM_ BO_ 544 "[P] Periodic";
CM_ BO_ 1369 "[PE] Periodic and On Event";
CM_ BO_ 520 "[E] On Event";
CM_ SG_ 520 META_STD_Country_OptADAS "This is the signal to inform whether the ADAS functions(HDA, NSCC)is operable or not 
in each country.";
CM_ SG_ 520 META_MessageType "This is Meta Data Message Type for Map Based ADAS.";
CM_ SG_ 520 META_MapProvider "This is Meta Data Map Provider for Map Based ADAS.";
CM_ SG_ 520 META_CountryCode "This is Meta Data Country Code for Map Based ADAS.";
CM_ SG_ 520 META_CyclicCounter "This is Meta Data Cyclic Counter for Map Based ADAS.";
CM_ SG_ 520 META_MajorProtocolVersion "This is Meta Data Major Protocol Version for Map Based ADAS.";
CM_ SG_ 520 META_HardwareVersion "This is Meta Data Hardware Version for Map Based ADAS.";
CM_ SG_ 520 META_DrivingSide "This is Meta Data Driving Side for Map Based ADAS.";
CM_ SG_ 520 META_RegionCode "This is Meta Data Region Code for Map Based ADAS.";
CM_ SG_ 520 META_MapVersionQuarter "This is Meta Data Map Version(Quarter) for Map Based ADAS.";
CM_ SG_ 520 META_MapVersionYear "This is Meta Data Map Version(Year) for Map Based ADAS.";
CM_ SG_ 520 META_SpeedUnit "This is Meta Dat Speed Unit for Map Based ADAS.";
CM_ SG_ 520 META_MinorProtocolVersion "This is Meta Data Minor Protocol Version for Map Based ADAS.";
CM_ BO_ 1363 "[PE] Periodic and On Event";
CM_ SG_ 1363 CF_Gway_ExtTailAct "This signal is for ¡°IPM (Gateway)¡± applied vehicles only.";
CM_ SG_ 1363 CF_Gway_AvTail "This signal is for ¡°IPM (Gateway)¡± applied vehicles only.";
CM_ SG_ 1363 CF_Gway_RearFogAct "This signal is for ¡°IPM (Gateway)¡± applied vehicles only.";
CM_ SG_ 1363 CF_Gway_RRDrSw "This signal is for ¡°IPM (Gateway)¡± applied vehicles only.";
CM_ SG_ 1363 CF_Gway_RLDrSw "This signal is for ¡°IPM (Gateway)¡± applied vehicles only.";
CM_ SG_ 1363 CF_Gway_IntTailAct "This signal is for ¡°IPM (Gateway)¡± applied vehicles only.";
CM_ SG_ 1363 CF_Gway_ESCLNotLockedWarn "This signal is for ¡°IPM (Gateway)¡± applied vehicles only.";
CM_ SG_ 1363 CF_Gway_IDoutWarn "This signal is for ¡°IPM (Gateway)¡± applied vehicles only.";
CM_ SG_ 1363 CF_Gway_ImmoLp "This signal is for ¡°IPM (Gateway)¡± applied vehicles only.";
CM_ SG_ 1363 CF_Gway_VehicleNotPWarn "This signal is for ¡°IPM (Gateway)¡± applied vehicles only.";
CM_ SG_ 1363 CF_Gway_DeactivationWarn "This signal is for ¡°IPM (Gateway)¡± applied vehicles only.";
CM_ SG_ 1363 CF_Gway_KeyBATDischargeWarn "This signal is for ¡°IPM (Gateway)¡± applied vehicles only.";
CM_ SG_ 1363 CF_Gway_WngBuz "This signal is for ¡°IPM (Gateway)¡± applied vehicles only.";
CM_ BO_ 1479 "[P] Periodic";
CM_ SG_ 1479 SCR_LEVEL_WARN_LAMP "SCR Inducement meessage for Passenger car";
CM_ SG_ 1479 SCR_LEVEL_WARN "SCR Inducement meessage for Passenger car";
CM_ SG_ 1479 SCR_SYS_ERROR_WARN "SCR Inducement meessage for Passenger car";
CM_ SG_ 1479 SCR_INDUCEMENT_EXIT_COND "SCR Inducement meessage for Passenger car";
CM_ SG_ 1479 SCR_UREA_LEVEL "SCR Inducement meessage for Passenger car";
CM_ SG_ 1479 SCR_REMAINING_DISTANCE "SCR Inducement meessage for Passenger car";
CM_ BO_ 1348 "[PE] Periodic and On Event";
CM_ SG_ 1348 NAVI_ISLWMapSource "Map source signal for ISLW with TOMTOM service in EU";
CM_ SG_ 1348 Navi_ISLW_CountryCode "Country Information From NAVI (ISO 3166-1 numeric values)";
CM_ SG_ 1348 Navi_ISLW_LinkClass "Link Class information from NAVI";
CM_ SG_ 1348 Navi_ISLW_SpdUnit "Unit of Speed Limit for ISLW from NAVI to Camera";
CM_ SG_ 1348 Navi_ISLW_Frwinfo "Freeway info for ISLW";
CM_ SG_ 1348 Navi_ISLW_SpdLimit "Speed Limit for ISLW from NAVI to Camera";
CM_ BO_ 809 "[P] Periodic";
CM_ SG_ 809 TQ_STND "1. In case of an engine which maximum engine torque is higher than 520Nm, this factor value is 15.
2. In case of Delphi ECU, Output period tolerance(+1ms) will be applied to Engine Lamda3.";
CM_ SG_ 809 CONF_TCU "1. For the automatic variant coding at E.O.L : This signal value is valid 1.5sec later from initial IG-ON
2. In case of Delphi ECU, Output period tolerance(+1ms) will be applied to Engine Lamda3.";
CM_ SG_ 809 MUL_CODE "In case of Delphi ECU, Output period tolerance(+1ms) will be applied to Engine Lamda3.";
CM_ SG_ 809 TEMP_ENG "In case of Delphi ECU, Output period tolerance(+1ms) will be applied to Engine Lamda3.";
CM_ SG_ 809 ACC_ACT "1. There is signal relationship between ¡®ACC_ACT¡¯ and ¡®PV_AV_CAN¡¯. See ¡®PV_AV_CAN¡¯ signal description page.
2. In case of Delphi ECU, Output period tolerance(+1ms) will be applied to Engine Lamda3.";
CM_ SG_ 809 BRAKE_ACT "In case of Delphi ECU, Output period tolerance(+1ms) will be applied to Engine Lamda3.";
CM_ SG_ 809 ENG_CHR "1. For the automatic variant coding at E.O.L : This signal value is valid 1.5sec later from initial IG-ON
2. In case of Delphi ECU, Output period tolerance(+1ms) will be applied to Engine Lamda3.";
CM_ SG_ 809 TPS "1. In diesel engine system, there is a signal relationship between TPS and PV_AV_CAN. For the details, please see PV_AV_CAN signal description page. 
2. In case of Delphi ECU, Output period tolerance(+1ms) will be applied to Engine Lamda3.";
CM_ SG_ 809 PV_AV_CAN "In case of Delphi ECU, Output period tolerance(+1ms) will be applied to Engine Lamda3.";
CM_ SG_ 809 ENG_VOL "In case of Delphi ECU, Output period tolerance(+1ms) will be applied to Engine Lamda3.";
CM_ BO_ 688 "[P] Periodic";
CM_ SG_ 688 CheckSum "When MDPS ECU sends this message, this message value is valid 1.5 sec later from IG-ON.";
CM_ BO_ 1107 "[P] Periodic";
CM_ SG_ 1107 CR_Fatc_OutTempSns "PT-CAN 4WD11 + FATC11 Indirect routing message. This ¨è is for the ¡°4WD ECU, MAGNA & WIA JVÞä¡± system applied vehicles only.";
CM_ BO_ 1345 "[PE] Periodic and On Event";
CM_ SG_ 1345 CF_Gway_LightSwState "This signal is for ¡°IPM (Gateway)¡± applied vehicles only.";
CM_ SG_ 1345 CF_Gway_TSigRHSw "This signal is for ¡°IPM (Gateway)¡± applied vehicles only.";
CM_ SG_ 1345 CF_Gway_TSigLHSw "This signal is for ¡°IPM (Gateway)¡± applied vehicles only.";
CM_ SG_ 1345 CF_Gway_DriveTypeOption "This signal is for ¡°IPM (Gateway)¡± applied vehicles only.";
CM_ SG_ 1345 CF_Gway_PassiveAccessLock "This signal is for ¡°IPM (Gateway)¡± applied vehicles only.";
CM_ SG_ 1345 CF_Gway_PassiveAccessUnlock "This signal is for ¡°IPM (Gateway)¡± applied vehicles only.";
CM_ SG_ 1345 CF_Gway_InhibitRMT "This signal is for ¡°IPM (Gateway)¡± applied vehicles only.";
CM_ BO_ 304 "[P] Periodic";
CM_ BO_ 1407 "[PE] Periodic and On Event";
CM_ BO_ 1397 "[E] On Event";
BA_DEF_ BO_  "DiagState" ENUM  "No","Yes";
BA_DEF_ BO_  "DiagResponse" ENUM  "No","Yes";
BA_DEF_ BO_  "DiagRequest" ENUM  "No","Yes";
BA_DEF_ SG_  "GenSigEnvVarType" ENUM  "Int","Float","Undef";
BA_DEF_ SG_  "GenSigEVName" STRING ;
BA_DEF_ SG_  "GenSigInactiveValue" INT 0 65535;
BA_DEF_ SG_  "GenSigSendType" ENUM  "Cyclic","OnWrite","OnWriteWithRepetition","OnChange","OnChangeWithRepetition","IfActive","IfActiveWithRepetition","NoSigSendType";
BA_DEF_ SG_  "GenSigStartValue" INT 0 1215752192;
BA_DEF_ SG_  "GwSigLatencyTime" INT 0 65535;
BA_DEF_ SG_  "GwSigMissingSourceType" ENUM  "Undef","OldValue","DefaultValue","InitialValue";
BA_DEF_ SG_  "SignalCategory" HEX 10 15;
BA_DEF_ BO_  "GenMsgCycleTime" INT 0 2000;
BA_DEF_ BO_  "GenMsgCycleTimeFast" INT 0 500;
BA_DEF_ BO_  "GenMsgDelayTime" INT 0 20;
BA_DEF_ BO_  "GenMsgILSupport" ENUM  "No","Yes";
BA_DEF_ BO_  "GenMsgNrOfRepetition" INT 0 3;
BA_DEF_ BO_  "GenMsgSendType" ENUM  "Cyclic","not_used","not_used","not_used","not_used","not_used","not_used","not_used","NoMsgSendType";
BA_DEF_ BO_  "GenMsgStartDelayTime" INT 0 2000;
BA_DEF_ BO_  "NmMessage" ENUM  "No","Yes";
BA_DEF_ BU_  "GenNodSleepTime" INT 1375 1650;
BA_DEF_ BU_  "ILUsed" ENUM  "No","Yes";
BA_DEF_ BU_  "NmCAN" INT 1 2;
BA_DEF_ BU_  "NmStationAddress" HEX 0 255;
BA_DEF_ BU_  "NodeLayerModules" STRING ;
BA_DEF_  "Baudrate" INT 50000 1000000;
BA_DEF_  "BusType" STRING ;
BA_DEF_  "GenEnvVarEndingDsp" STRING ;
BA_DEF_  "GenEnvVarEndingSnd" STRING ;
BA_DEF_  "GenEnvVarPrefix" STRING ;
BA_DEF_  "GenNWMApBusSleep" STRING ;
BA_DEF_  "GenNWMApCanNormal" STRING ;
BA_DEF_  "GenNWMApCanOff" STRING ;
BA_DEF_  "GenNWMApCanOn" STRING ;
BA_DEF_  "GenNWMApCanSleep" STRING ;
BA_DEF_  "GenNWMApCanWakeUp" STRING ;
BA_DEF_  "GenNWMGotoMode_Awake" STRING ;
BA_DEF_  "GenNWMGotoMode_BusSleep" STRING ;
BA_DEF_  "GenNWMSleepTime" INT 1375 1650;
BA_DEF_  "GenNWMTalkNM" STRING ;
BA_DEF_  "Manufacturer" STRING ;
BA_DEF_  "NmBaseAddress" HEX 0 2047;
BA_DEF_  "NmMessageCount" INT 0 128;
BA_DEF_  "NmType" STRING ;
BA_DEF_  "SamplePointMax" INT 50 85;
BA_DEF_  "SamplePointMin" INT 55 85;
BA_DEF_  "SyncJumpWidthMax" INT 1 8;
BA_DEF_  "SyncJumpWidthMin" INT 1 4;
BA_DEF_  "VersionDay" INT 1 31;
BA_DEF_  "VersionMonth" INT 1 12;
BA_DEF_  "VersionWeek" INT 1 53;
BA_DEF_  "VersionYear" INT 0 9999;
BA_DEF_REL_ BU_SG_REL_  "GenSigTimeoutTime" INT 0 7000;
BA_DEF_DEF_  "DiagState" "No";
BA_DEF_DEF_  "DiagResponse" "No";
BA_DEF_DEF_  "DiagRequest" "No";
BA_DEF_DEF_  "GenSigEnvVarType" "Undef";
BA_DEF_DEF_  "GenSigEVName" "@Signame";
BA_DEF_DEF_  "GenSigInactiveValue" 0;
BA_DEF_DEF_  "GenSigSendType" "NoSigSendType";
BA_DEF_DEF_  "GenSigStartValue" 0;
BA_DEF_DEF_  "GwSigLatencyTime" 40;
BA_DEF_DEF_  "GwSigMissingSourceType" "Undef";
BA_DEF_DEF_  "SignalCategory" 12;
BA_DEF_DEF_  "GenMsgCycleTime" 10;
BA_DEF_DEF_  "GenMsgCycleTimeFast" 40;
BA_DEF_DEF_  "GenMsgDelayTime" 20;
BA_DEF_DEF_  "GenMsgILSupport" "Yes";
BA_DEF_DEF_  "GenMsgNrOfRepetition" 0;
BA_DEF_DEF_  "GenMsgSendType" "Cyclic";
BA_DEF_DEF_  "GenMsgStartDelayTime" 0;
BA_DEF_DEF_  "NmMessage" "No";
BA_DEF_DEF_  "GenNodSleepTime" 1500;
BA_DEF_DEF_  "ILUsed" "Yes";
BA_DEF_DEF_  "NmCAN" 1;
BA_DEF_DEF_  "NmStationAddress" 0;
BA_DEF_DEF_  "NodeLayerModules" "oseknm01.dll";
BA_DEF_DEF_  "Baudrate" 500000;
BA_DEF_DEF_  "BusType" "CAN";
BA_DEF_DEF_  "GenEnvVarEndingDsp" "Dsp_";
BA_DEF_DEF_  "GenEnvVarEndingSnd" "_";
BA_DEF_DEF_  "GenEnvVarPrefix" "Env";
BA_DEF_DEF_  "GenNWMApBusSleep" "ApplNmCanBusSleep()";
BA_DEF_DEF_  "GenNWMApCanNormal" "ApplNmCanNormal()";
BA_DEF_DEF_  "GenNWMApCanOff" "ApplCanOffline()";
BA_DEF_DEF_  "GenNWMApCanOn" "ApplCanOnline()";
BA_DEF_DEF_  "GenNWMApCanSleep" "ApplNmCanSleep()";
BA_DEF_DEF_  "GenNWMApCanWakeUp" "ApplCanWakeUp()";
BA_DEF_DEF_  "GenNWMGotoMode_Awake" "GotoMode_Awake()";
BA_DEF_DEF_  "GenNWMGotoMode_BusSleep" "GotoMode_BusSleep()";
BA_DEF_DEF_  "GenNWMSleepTime" 1500;
BA_DEF_DEF_  "GenNWMTalkNM" "TalkNM()";
BA_DEF_DEF_  "Manufacturer" "HMC";
BA_DEF_DEF_  "NmBaseAddress" 1024;
BA_DEF_DEF_  "NmMessageCount" 128;
BA_DEF_DEF_  "NmType" "Vector";
BA_DEF_DEF_  "SamplePointMax" 82;
BA_DEF_DEF_  "SamplePointMin" 75;
BA_DEF_DEF_  "SyncJumpWidthMax" 3;
BA_DEF_DEF_  "SyncJumpWidthMin" 2;
BA_DEF_DEF_  "VersionDay" 1;
BA_DEF_DEF_  "VersionMonth" 1;
BA_DEF_DEF_  "VersionWeek" 1;
BA_DEF_DEF_  "VersionYear" 2010;
BA_DEF_DEF_REL_ "GenSigTimeoutTime" 500;
BA_ "GenMsgCycleTime" BO_ 1183 200;
BA_ "GenMsgCycleTime" BO_ 1260 100;
BA_ "GenMsgCycleTime" BO_ 2679898134 100;
BA_ "GenMsgCycleTime" BO_ 2679898133 100;
BA_ "GenMsgCycleTime" BO_ 2679898132 100;
BA_ "GenMsgCycleTime" BO_ 2679898131 100;
BA_ "GenMsgCycleTime" BO_ 2679898130 100;
BA_ "GenMsgCycleTime" BO_ 1155 200;
BA_ "GenMsgNrOfRepetition" BO_ 1190 3;
BA_ "GenMsgCycleTime" BO_ 1190 200;
BA_ "GenMsgSendType" BO_ 1729 8;
BA_ "GenMsgILSupport" BO_ 1729 0;
BA_ "GenMsgDelayTime" BO_ 1729 0;
BA_ "GenMsgCycleTimeFast" BO_ 1729 0;
BA_ "GenMsgCycleTime" BO_ 1729 0;
BA_ "GenMsgSendType" BO_ 1728 8;
BA_ "GenMsgILSupport" BO_ 1728 0;
BA_ "GenMsgDelayTime" BO_ 1728 0;
BA_ "GenMsgCycleTimeFast" BO_ 1728 0;
BA_ "GenMsgCycleTime" BO_ 1728 0;
BA_ "GenMsgCycleTime" BO_ 2008 0;
BA_ "GenMsgNrOfRepetition" BO_ 2008 3;
BA_ "GenMsgSendType" BO_ 2008 8;
BA_ "GenMsgCycleTime" BO_ 2000 0;
BA_ "GenMsgNrOfRepetition" BO_ 2000 3;
BA_ "GenMsgSendType" BO_ 2000 8;
BA_ "DiagRequest" BO_ 1988 1;
BA_ "GenMsgSendType" BO_ 1988 8;
BA_ "GenMsgNrOfRepetition" BO_ 1988 3;
BA_ "GenMsgCycleTime" BO_ 1988 0;
BA_ "DiagResponse" BO_ 1996 1;
BA_ "GenMsgSendType" BO_ 1996 8;
BA_ "GenMsgNrOfRepetition" BO_ 1996 3;
BA_ "GenMsgCycleTime" BO_ 1996 0;
BA_ "GenMsgSendType" BO_ 550 8;
BA_ "GenMsgCycleTime" BO_ 550 0;
BA_ "GenMsgNrOfRepetition" BO_ 550 3;
BA_ "GenMsgSendType" BO_ 528 8;
BA_ "GenMsgCycleTime" BO_ 528 0;
BA_ "GenMsgNrOfRepetition" BO_ 528 3;
BA_ "GenMsgSendType" BO_ 524 8;
BA_ "GenMsgCycleTime" BO_ 524 0;
BA_ "GenMsgNrOfRepetition" BO_ 524 3;
BA_ "GenMsgCycleTime" BO_ 1371 600;
BA_ "GenMsgNrOfRepetition" BO_ 1371 3;
BA_ "GenMsgSendType" BO_ 516 8;
BA_ "GenMsgCycleTime" BO_ 516 0;
BA_ "GenMsgNrOfRepetition" BO_ 516 3;
BA_ "GenMsgSendType" BO_ 532 8;
BA_ "GenMsgCycleTime" BO_ 532 0;
BA_ "GenMsgNrOfRepetition" BO_ 532 3;
BA_ "GenMsgCycleTime" BO_ 1369 200;
BA_ "GenMsgNrOfRepetition" BO_ 1369 3;
BA_ "GenMsgSendType" BO_ 520 8;
BA_ "GenMsgCycleTime" BO_ 520 0;
BA_ "GenMsgNrOfRepetition" BO_ 520 3;
BA_ "GenMsgCycleTime" BO_ 1363 200;
BA_ "GenMsgNrOfRepetition" BO_ 1363 3;
BA_ "GenMsgCycleTime" BO_ 1479 100;
BA_ "GenMsgCycleTime" BO_ 1348 200;
BA_ "GenMsgNrOfRepetition" BO_ 1348 3;
BA_ "GenMsgCycleTime" BO_ 1107 20;
BA_ "GenMsgCycleTime" BO_ 1345 100;
BA_ "GenMsgNrOfRepetition" BO_ 1345 3;
BA_ "GenMsgCycleTime" BO_ 1407 2000;
BA_ "GenMsgNrOfRepetition" BO_ 1407 3;
BA_ "GenMsgSendType" BO_ 1397 8;
BA_ "GenMsgCycleTime" BO_ 1397 0;
BA_ "GenMsgNrOfRepetition" BO_ 1397 3;
BA_ "GenSigSendType" SG_ 3221225472 FRM_FORMAT 4;
BA_ "GenSigSendType" SG_ 3221225472 SID 4;
BA_ "GenSigSendType" SG_ 3221225472 REQ_RESPONSE 4;
BA_ "GwSigLatencyTime" SG_ 1260 ISLA_OptUsmSta 50;
BA_ "GenSigStartValue" SG_ 1155 FCA_DrvSetState 2;
BA_ "GenSigStartValue" SG_ 1155 FCA_USM 3;
BA_ "GenSigSendType" SG_ 550 STUB_MessageType 4;
BA_ "GenSigStartValue" SG_ 550 STUB_MessageType 7;
BA_ "GenSigSendType" SG_ 550 STUB_Offset 4;
BA_ "GenSigStartValue" SG_ 550 STUB_Offset 8191;
BA_ "GenSigSendType" SG_ 550 STUB_CyclicCounter 4;
BA_ "GenSigSendType" SG_ 550 STUB_PathIndex 4;
BA_ "GenSigSendType" SG_ 550 STUB_SubPathIndex 4;
BA_ "GenSigSendType" SG_ 550 STUB_Retransmission 4;
BA_ "GenSigSendType" SG_ 550 STUB_Update 4;
BA_ "GenSigSendType" SG_ 550 STUB_RelativeProbability 4;
BA_ "GenSigStartValue" SG_ 550 STUB_RelativeProbability 31;
BA_ "GenSigSendType" SG_ 550 STUB_FunctionalRoadClass 4;
BA_ "GenSigStartValue" SG_ 550 STUB_FunctionalRoadClass 7;
BA_ "GenSigSendType" SG_ 550 STUB_CalculatedRoute 4;
BA_ "GenSigStartValue" SG_ 550 STUB_CalculatedRoute 3;
BA_ "GenSigSendType" SG_ 550 STUB_ComplexIntersection 4;
BA_ "GenSigStartValue" SG_ 550 STUB_ComplexIntersection 3;
BA_ "GenSigSendType" SG_ 550 STUB_FormOfWay 4;
BA_ "GenSigStartValue" SG_ 550 STUB_FormOfWay 15;
BA_ "GenSigSendType" SG_ 550 STUB_TurnAngle 4;
BA_ "GenSigStartValue" SG_ 550 STUB_TurnAngle 255;
BA_ "GenSigSendType" SG_ 550 STUB_LastStubAtOffset 4;
BA_ "GenSigSendType" SG_ 550 STUB_RightOfWay 4;
BA_ "GenSigStartValue" SG_ 550 STUB_RightOfWay 3;
BA_ "GenSigSendType" SG_ 550 STUB_OppositeLanes 4;
BA_ "GenSigStartValue" SG_ 550 STUB_OppositeLanes 3;
BA_ "GenSigSendType" SG_ 550 STUB_DirectionLanes 4;
BA_ "GenSigStartValue" SG_ 550 STUB_DirectionLanes 7;
BA_ "GenSigSendType" SG_ 528 PROSHORT_MessageType 4;
BA_ "GenSigStartValue" SG_ 528 PROSHORT_MessageType 7;
BA_ "GenSigSendType" SG_ 528 PROSHORT_Offset 4;
BA_ "GenSigStartValue" SG_ 528 PROSHORT_Offset 8191;
BA_ "GenSigSendType" SG_ 528 PROSHORT_CyclicCounter 4;
BA_ "GenSigSendType" SG_ 528 PROSHORT_PathIndex 4;
BA_ "GenSigSendType" SG_ 528 PROSHORT_Accuracy 4;
BA_ "GenSigStartValue" SG_ 528 PROSHORT_Accuracy 3;
BA_ "GenSigSendType" SG_ 528 PROSHORT_Distance 4;
BA_ "GenSigStartValue" SG_ 528 PROSHORT_Distance 1023;
BA_ "GenSigSendType" SG_ 528 PROSHORT_Value0 4;
BA_ "GenSigStartValue" SG_ 528 PROSHORT_Value0 1023;
BA_ "GenSigSendType" SG_ 528 PROSHORT_Value1 4;
BA_ "GenSigSendType" SG_ 528 PROSHORT_ProfileType 4;
BA_ "GenSigSendType" SG_ 528 PROSHORT_ControlPoint 4;
BA_ "GenSigSendType" SG_ 528 PROSHORT_Retransmission 4;
BA_ "GenSigSendType" SG_ 528 PROSHORT_Update 4;
BA_ "GenSigSendType" SG_ 524 SEG_MessageType 4;
BA_ "GenSigStartValue" SG_ 524 SEG_MessageType 7;
BA_ "GenSigSendType" SG_ 524 SEG_Offset 4;
BA_ "GenSigStartValue" SG_ 524 SEG_Offset 8191;
BA_ "GenSigSendType" SG_ 524 SEG_CyclicCounter 4;
BA_ "GenSigSendType" SG_ 524 SEG_PathIndex 4;
BA_ "GenSigSendType" SG_ 524 SEG_Tunnel 4;
BA_ "GenSigStartValue" SG_ 524 SEG_Tunnel 3;
BA_ "GenSigSendType" SG_ 524 SEG_Bridge 4;
BA_ "GenSigStartValue" SG_ 524 SEG_Bridge 3;
BA_ "GenSigSendType" SG_ 524 SEG_BuiltUpArea 4;
BA_ "GenSigStartValue" SG_ 524 SEG_BuiltUpArea 3;
BA_ "GenSigSendType" SG_ 524 SEG_Retransmission 4;
BA_ "GenSigSendType" SG_ 524 SEG_Update 4;
BA_ "GenSigSendType" SG_ 524 SEG_RelativeProbability 4;
BA_ "GenSigStartValue" SG_ 524 SEG_RelativeProbability 31;
BA_ "GenSigSendType" SG_ 524 SEG_FunctionalRoadClass 4;
BA_ "GenSigStartValue" SG_ 524 SEG_FunctionalRoadClass 7;
BA_ "GenSigSendType" SG_ 524 SEG_CalculatedRoute 4;
BA_ "GenSigStartValue" SG_ 524 SEG_CalculatedRoute 3;
BA_ "GenSigSendType" SG_ 524 SEG_ComplexIntersection 4;
BA_ "GenSigStartValue" SG_ 524 SEG_ComplexIntersection 3;
BA_ "GenSigSendType" SG_ 524 SEG_FormOfWay 4;
BA_ "GenSigStartValue" SG_ 524 SEG_FormOfWay 15;
BA_ "GenSigSendType" SG_ 524 SEG_SpeedLimit 4;
BA_ "GenSigStartValue" SG_ 524 SEG_SpeedLimit 31;
BA_ "GenSigSendType" SG_ 524 SEG_SpeedLimitType 4;
BA_ "GenSigStartValue" SG_ 524 SEG_SpeedLimitType 7;
BA_ "GenSigSendType" SG_ 524 SEG_DividedRoad 4;
BA_ "GenSigStartValue" SG_ 524 SEG_DividedRoad 3;
BA_ "GenSigSendType" SG_ 524 SEG_OppositeLanes 4;
BA_ "GenSigStartValue" SG_ 524 SEG_OppositeLanes 3;
BA_ "GenSigSendType" SG_ 524 SEG_DirectionLanes 4;
BA_ "GenSigStartValue" SG_ 524 SEG_DirectionLanes 7;
BA_ "GenSigSendType" SG_ 1371 AVM_View 4;
BA_ "GenSigStartValue" SG_ 1371 AVM_View 31;
BA_ "GenSigSendType" SG_ 1371 AVM_Display_Message 4;
BA_ "GenSigStartValue" SG_ 1371 AVM_Display_Message 255;
BA_ "GenSigSendType" SG_ 1371 AVM_Option 4;
BA_ "GenSigStartValue" SG_ 1371 AVM_Option 15;
BA_ "GenSigSendType" SG_ 1371 AVM_Btn_Show 4;
BA_ "GenSigSendType" SG_ 1371 AVM_HU_RearView_Option 4;
BA_ "GenSigStartValue" SG_ 1371 AVM_HU_RearView_Option 15;
BA_ "GenSigSendType" SG_ 1371 AVM_HU_FrontView_Option 4;
BA_ "GenSigStartValue" SG_ 1371 AVM_HU_FrontView_Option 15;
BA_ "GenSigSendType" SG_ 1371 AVM_Version 4;
BA_ "GenSigStartValue" SG_ 1371 AVM_Version 65535;
BA_ "GenSigSendType" SG_ 516 POS_MessageType 4;
BA_ "GenSigStartValue" SG_ 516 POS_MessageType 7;
BA_ "GenSigSendType" SG_ 516 POS_Offset 4;
BA_ "GenSigStartValue" SG_ 516 POS_Offset 8191;
BA_ "GenSigSendType" SG_ 516 POS_CyclicCounter 4;
BA_ "GenSigSendType" SG_ 516 POS_PathIndex 4;
BA_ "GenSigSendType" SG_ 516 POS_PositionIndex 4;
BA_ "GenSigStartValue" SG_ 516 POS_PositionIndex 3;
BA_ "GenSigSendType" SG_ 516 POS_PositionProbability 4;
BA_ "GenSigStartValue" SG_ 516 POS_PositionProbability 31;
BA_ "GenSigSendType" SG_ 516 POS_PositionAge 4;
BA_ "GenSigStartValue" SG_ 516 POS_PositionAge 511;
BA_ "GenSigSendType" SG_ 516 POS_PositionConfidence 4;
BA_ "GenSigStartValue" SG_ 516 POS_PositionConfidence 7;
BA_ "GenSigSendType" SG_ 516 POS_CurrentLane 4;
BA_ "GenSigStartValue" SG_ 516 POS_CurrentLane 7;
BA_ "GenSigSendType" SG_ 516 POS_RangeAvgSpeed 4;
BA_ "GenSigStartValue" SG_ 516 POS_RangeAvgSpeed 511;
BA_ "GenSigSendType" SG_ 516 POS_RelativeHeading 4;
BA_ "GenSigStartValue" SG_ 516 POS_RelativeHeading 255;
BA_ "GenSigSendType" SG_ 532 PROLONG_Value 4;
BA_ "GenSigSendType" SG_ 532 PROLONG_MessageType 4;
BA_ "GenSigStartValue" SG_ 532 PROLONG_MessageType 7;
BA_ "GenSigSendType" SG_ 532 PROLONG_Offset 4;
BA_ "GenSigStartValue" SG_ 532 PROLONG_Offset 8191;
BA_ "GenSigSendType" SG_ 532 PROLONG_CyclicCounter 4;
BA_ "GenSigSendType" SG_ 532 PROLONG_PathIndex 4;
BA_ "GenSigSendType" SG_ 532 PROLONG_ProfileType 4;
BA_ "GenSigSendType" SG_ 532 PROLONG_CountrolPoint 4;
BA_ "GenSigSendType" SG_ 532 PROLONG_Retransmission 4;
BA_ "GenSigSendType" SG_ 532 PROLONG_Update 4;
BA_ "GenSigSendType" SG_ 1369 CF_Gway_MemoryP1Cmd 4;
BA_ "GenSigSendType" SG_ 1369 CF_Gway_MemoryP2Cmd 4;
BA_ "GenSigSendType" SG_ 1369 CF_Gway_PBackP1Cmd 4;
BA_ "GenSigSendType" SG_ 1369 CF_Gway_PBackP2Cmd 4;
BA_ "GenSigSendType" SG_ 1369 CF_Gway_PBackStopCmd 4;
BA_ "GenSigSendType" SG_ 1369 CF_Gway_DrvWdwStat 4;
BA_ "GenSigSendType" SG_ 1369 CF_Gway_RLWdwState 4;
BA_ "GenSigSendType" SG_ 1369 CF_Gway_RRWdwState 4;
BA_ "GenSigSendType" SG_ 1369 CF_Gway_AstWdwStat 4;
BA_ "GenSigSendType" SG_ 1369 CF_Gway_MemoryEnable 4;
BA_ "GenSigSendType" SG_ 1369 CF_Gway_IMSBuzzer 4;
BA_ "GenSigSendType" SG_ 1369 C_HSWSSysStat 4;
BA_ "GenSigSendType" SG_ 1369 CF_Gway_WiperSwState 4;
BA_ "GenSigSendType" SG_ 1369 CF_Gway_HCIMSPBackCmd 4;
BA_ "GenSigSendType" SG_ 1369 CF_Gway_DrvSeatBeltIND 4;
BA_ "GenSigSendType" SG_ 1369 CF_Gway_AstSeatBeltIND 4;
BA_ "GenSigSendType" SG_ 1369 CF_Gway_RCSeatBeltIND 4;
BA_ "GenSigSendType" SG_ 1369 CF_Gway_RLSeatBeltIND 4;
BA_ "GenSigSendType" SG_ 1369 CF_Gway_RRSeatBeltIND 4;
BA_ "GenSigSendType" SG_ 1369 CF_Gway_WPCWarning 4;
BA_ "GenSigSendType" SG_ 1369 CF_Gway_SeatBeltWngBuz 4;
BA_ "GenSigSendType" SG_ 520 META_MessageType 4;
BA_ "GenSigStartValue" SG_ 520 META_MessageType 7;
BA_ "GenSigSendType" SG_ 520 META_MapProvider 4;
BA_ "GenSigStartValue" SG_ 520 META_MapProvider 7;
BA_ "GenSigSendType" SG_ 520 META_CountryCode 4;
BA_ "GenSigStartValue" SG_ 520 META_CountryCode 1023;
BA_ "GenSigSendType" SG_ 520 META_CyclicCounter 4;
BA_ "GenSigSendType" SG_ 520 META_MajorProtocolVersion 4;
BA_ "GenSigSendType" SG_ 520 META_MinorProtocolSubVer 4;
BA_ "GenSigSendType" SG_ 520 META_HardwareVersion 4;
BA_ "GenSigStartValue" SG_ 520 META_HardwareVersion 511;
BA_ "GenSigSendType" SG_ 520 META_DrivingSide 4;
BA_ "GenSigSendType" SG_ 520 META_RegionCode 4;
BA_ "GenSigStartValue" SG_ 520 META_RegionCode 32767;
BA_ "GenSigSendType" SG_ 520 META_MapVersionQuarter 4;
BA_ "GenSigSendType" SG_ 520 META_MapVersionYear 4;
BA_ "GenSigStartValue" SG_ 520 META_MapVersionYear 63;
BA_ "GenSigSendType" SG_ 520 META_SpeedUnit 4;
BA_ "GenSigSendType" SG_ 520 META_MinorProtocolVersion 4;
BA_ "GenSigSendType" SG_ 1363 CF_Gway_ExtTailAct 4;
BA_ "GenSigSendType" SG_ 1363 CF_Gway_AutoLightValue 4;
BA_ "GenSigSendType" SG_ 1363 CF_Gway_BrakeFluidSw 4;
BA_ "GenSigSendType" SG_ 1363 CF_Gway_AvTail 4;
BA_ "GenSigSendType" SG_ 1363 CF_Gway_RearFogAct 4;
BA_ "GenSigSendType" SG_ 1363 CF_Gway_RRDrSw 4;
BA_ "GenSigSendType" SG_ 1363 CF_Gway_RLDrSw 4;
BA_ "GenSigSendType" SG_ 1363 CF_Gway_IntTailAct 4;
BA_ "GenSigSendType" SG_ 1363 CF_Gway_WiperParkPosition 4;
BA_ "GenSigSendType" SG_ 1363 CF_Gway_ESCLNotLockedWarn 4;
BA_ "GenSigSendType" SG_ 1363 CF_Gway_IDoutWarn 4;
BA_ "GenSigSendType" SG_ 1363 CF_Gway_ImmoLp 4;
BA_ "GenSigSendType" SG_ 1363 CF_Gway_VehicleNotPWarn 4;
BA_ "GenSigSendType" SG_ 1363 CF_Gway_DeactivationWarn 4;
BA_ "GenSigSendType" SG_ 1363 CF_Gway_KeyBATDischargeWarn 4;
BA_ "GenSigSendType" SG_ 1363 CF_Gway_SJBDeliveryMode 4;
BA_ "GenSigStartValue" SG_ 1363 CF_Gway_SJBDeliveryMode 1;
BA_ "GenSigSendType" SG_ 1363 CF_Gway_SMKDispWarn 4;
BA_ "GenSigSendType" SG_ 1363 CF_Gway_WngBuz 4;
BA_ "GenSigSendType" SG_ 1348 HU_AliveStatus 4;
BA_ "GenSigStartValue" SG_ 1348 HU_AliveStatus 3;
BA_ "GenSigStartValue" SG_ 809 TEMP_ENG 255;
BA_ "GenSigStartValue" SG_ 809 BRAKE_ACT 1;
BA_ "GenSigStartValue" SG_ 809 TPS 32;
BA_ "GenSigStartValue" SG_ 688 SAS_Stat 7;
BA_ "GenSigSendType" SG_ 1345 CF_Gway_IGNSw 4;
BA_ "GenSigSendType" SG_ 1345 CF_Gway_RKECmd 4;
BA_ "GenSigSendType" SG_ 1345 CF_Gway_DrvDrSw 4;
BA_ "GenSigSendType" SG_ 1345 CF_Gway_DrvSeatBeltSw 4;
BA_ "GenSigSendType" SG_ 1345 CF_Gway_TrunkTgSw 4;
BA_ "GenSigSendType" SG_ 1345 CF_Gway_SMKOption 4;
BA_ "GenSigSendType" SG_ 1345 CF_Gway_HoodSw 4;
BA_ "GenSigSendType" SG_ 1345 CF_Gway_TurnSigLh 4;
BA_ "GenSigSendType" SG_ 1345 CF_Gway_WiperIntT 4;
BA_ "GenSigSendType" SG_ 1345 CF_Gway_WiperIntSw 4;
BA_ "GenSigSendType" SG_ 1345 CF_Gway_WiperLowSw 4;
BA_ "GenSigSendType" SG_ 1345 CF_Gway_WiperHighSw 4;
BA_ "GenSigSendType" SG_ 1345 CF_Gway_WiperAutoSw 4;
BA_ "GenSigSendType" SG_ 1345 CF_Gway_HeadLampLow 4;
BA_ "GenSigSendType" SG_ 1345 CF_Gway_HeadLampHigh 4;
BA_ "GenSigSendType" SG_ 1345 CF_Gway_HazardSw 4;
BA_ "GenSigSendType" SG_ 1345 CF_Gway_AstDrSw 4;
BA_ "GenSigSendType" SG_ 1345 CF_Gway_LightSwState 4;
BA_ "GenSigSendType" SG_ 1345 CF_Gway_TSigRHSw 4;
BA_ "GenSigSendType" SG_ 1345 CF_Gway_TSigLHSw 4;
BA_ "GenSigSendType" SG_ 1345 CF_Gway_DriveTypeOption 4;
BA_ "GenSigSendType" SG_ 1345 CF_Gway_PassiveAccessLock 4;
BA_ "GenSigSendType" SG_ 1345 CF_Gway_PassiveAccessUnlock 4;
BA_ "GenSigSendType" SG_ 1345 CF_Gway_PassingSW 4;
BA_ "GenSigSendType" SG_ 1345 CF_Gway_HBAControlMode 4;
BA_ "GenSigSendType" SG_ 1345 CF_Gway_InhibitRMT 4;
BA_ "GenSigSendType" SG_ 1345 CF_Gway_RainSnsOption 4;
BA_ "GenSigSendType" SG_ 1345 C_SunRoofOpenState 4;
BA_ "GenSigSendType" SG_ 1345 CF_Gway_ParkBrakeSw 4;
BA_ "GenSigSendType" SG_ 1345 CF_Gway_TurnSigRh 4;
BA_ "GenSigStartValue" SG_ 304 CR_Yrs_Yr 32768;
BA_ "GenSigStartValue" SG_ 304 CR_Yrs_LatAc 32768;
BA_ "GenSigStartValue" SG_ 304 CF_Yrs_YrStat 2;
BA_ "GenSigStartValue" SG_ 304 CF_Yrs_LatAcStat 2;
BA_ "GenSigSendType" SG_ 1407 HU_Type 4;
BA_ "GenSigStartValue" SG_ 1407 HU_Type 255;
BA_ "GenSigSendType" SG_ 1407 HU_DistributeInfo 4;
BA_ "GenSigStartValue" SG_ 1407 HU_DistributeInfo 255;
BA_ "GenSigSendType" SG_ 1407 HU_AdasSupport 4;
BA_ "GenSigSendType" SG_ 1397 HU_AVM_Cal_Cmd 4;
BA_ "GenSigStartValue" SG_ 1397 HU_AVM_Cal_Cmd 15;
BA_ "GenSigSendType" SG_ 1397 HU_AVM_PT_X 4;
BA_ "GenSigStartValue" SG_ 1397 HU_AVM_PT_X 4095;
BA_ "GenSigSendType" SG_ 1397 HU_AVM_PT_Y 4;
BA_ "GenSigStartValue" SG_ 1397 HU_AVM_PT_Y 4095;
BA_ "GenSigSendType" SG_ 1397 HU_AVM_SelectedMenu 4;
BA_ "GenSigStartValue" SG_ 1397 HU_AVM_SelectedMenu 31;
BA_ "GenSigSendType" SG_ 1397 HU_AVM_CameraOff 4;
BA_ "GenSigStartValue" SG_ 1397 HU_AVM_CameraOff 3;
BA_ "GenSigSendType" SG_ 1397 HU_AVM_Option 4;
BA_ "GenSigStartValue" SG_ 1397 HU_AVM_Option 15;
BA_ "GenSigSendType" SG_ 1397 HU_AVM_RearView_Option 4;
BA_ "GenSigStartValue" SG_ 1397 HU_AVM_RearView_Option 15;
BA_ "GenSigSendType" SG_ 1397 HU_AVM_FrontView_Option 4;
BA_ "GenSigStartValue" SG_ 1397 HU_AVM_FrontView_Option 15;
BA_REL_ "GenSigTimeoutTime" BU_SG_REL_ FR_CMR SG_ 550 STUB_MessageType 0;
BA_REL_ "GenSigTimeoutTime" BU_SG_REL_ SCC SG_ 550 STUB_MessageType 0;
BA_REL_ "GenSigTimeoutTime" BU_SG_REL_ FR_CMR SG_ 550 STUB_Offset 0;
BA_REL_ "GenSigTimeoutTime" BU_SG_REL_ SCC SG_ 550 STUB_Offset 0;
BA_REL_ "GenSigTimeoutTime" BU_SG_REL_ FR_CMR SG_ 550 STUB_CyclicCounter 0;
BA_REL_ "GenSigTimeoutTime" BU_SG_REL_ SCC SG_ 550 STUB_CyclicCounter 0;
BA_REL_ "GenSigTimeoutTime" BU_SG_REL_ FR_CMR SG_ 550 STUB_PathIndex 0;
BA_REL_ "GenSigTimeoutTime" BU_SG_REL_ SCC SG_ 550 STUB_PathIndex 0;
BA_REL_ "GenSigTimeoutTime" BU_SG_REL_ FR_CMR SG_ 550 STUB_SubPathIndex 0;
BA_REL_ "GenSigTimeoutTime" BU_SG_REL_ SCC SG_ 550 STUB_SubPathIndex 0;
BA_REL_ "GenSigTimeoutTime" BU_SG_REL_ FR_CMR SG_ 550 STUB_Retransmission 0;
BA_REL_ "GenSigTimeoutTime" BU_SG_REL_ SCC SG_ 550 STUB_Retransmission 0;
BA_REL_ "GenSigTimeoutTime" BU_SG_REL_ FR_CMR SG_ 550 STUB_Update 0;
BA_REL_ "GenSigTimeoutTime" BU_SG_REL_ SCC SG_ 550 STUB_Update 0;
BA_REL_ "GenSigTimeoutTime" BU_SG_REL_ FR_CMR SG_ 550 STUB_RelativeProbability 0;
BA_REL_ "GenSigTimeoutTime" BU_SG_REL_ SCC SG_ 550 STUB_RelativeProbability 0;
BA_REL_ "GenSigTimeoutTime" BU_SG_REL_ FR_CMR SG_ 550 STUB_FunctionalRoadClass 0;
BA_REL_ "GenSigTimeoutTime" BU_SG_REL_ SCC SG_ 550 STUB_FunctionalRoadClass 0;
BA_REL_ "GenSigTimeoutTime" BU_SG_REL_ FR_CMR SG_ 550 STUB_CalculatedRoute 0;
BA_REL_ "GenSigTimeoutTime" BU_SG_REL_ SCC SG_ 550 STUB_CalculatedRoute 0;
BA_REL_ "GenSigTimeoutTime" BU_SG_REL_ FR_CMR SG_ 550 STUB_ComplexIntersection 0;
BA_REL_ "GenSigTimeoutTime" BU_SG_REL_ SCC SG_ 550 STUB_ComplexIntersection 0;
BA_REL_ "GenSigTimeoutTime" BU_SG_REL_ FR_CMR SG_ 550 STUB_FormOfWay 0;
BA_REL_ "GenSigTimeoutTime" BU_SG_REL_ SCC SG_ 550 STUB_FormOfWay 0;
BA_REL_ "GenSigTimeoutTime" BU_SG_REL_ FR_CMR SG_ 550 STUB_TurnAngle 0;
BA_REL_ "GenSigTimeoutTime" BU_SG_REL_ SCC SG_ 550 STUB_TurnAngle 0;
BA_REL_ "GenSigTimeoutTime" BU_SG_REL_ FR_CMR SG_ 550 STUB_LastStubAtOffset 0;
BA_REL_ "GenSigTimeoutTime" BU_SG_REL_ SCC SG_ 550 STUB_LastStubAtOffset 0;
BA_REL_ "GenSigTimeoutTime" BU_SG_REL_ FR_CMR SG_ 550 STUB_RightOfWay 0;
BA_REL_ "GenSigTimeoutTime" BU_SG_REL_ SCC SG_ 550 STUB_RightOfWay 0;
BA_REL_ "GenSigTimeoutTime" BU_SG_REL_ FR_CMR SG_ 550 STUB_OppositeLanes 0;
BA_REL_ "GenSigTimeoutTime" BU_SG_REL_ SCC SG_ 550 STUB_OppositeLanes 0;
BA_REL_ "GenSigTimeoutTime" BU_SG_REL_ FR_CMR SG_ 550 STUB_DirectionLanes 0;
BA_REL_ "GenSigTimeoutTime" BU_SG_REL_ SCC SG_ 550 STUB_DirectionLanes 0;
BA_REL_ "GenSigTimeoutTime" BU_SG_REL_ FR_CMR SG_ 528 PROSHORT_MessageType 0;
BA_REL_ "GenSigTimeoutTime" BU_SG_REL_ SCC SG_ 528 PROSHORT_MessageType 0;
BA_REL_ "GenSigTimeoutTime" BU_SG_REL_ FR_CMR SG_ 528 PROSHORT_Offset 0;
BA_REL_ "GenSigTimeoutTime" BU_SG_REL_ SCC SG_ 528 PROSHORT_Offset 0;
BA_REL_ "GenSigTimeoutTime" BU_SG_REL_ FR_CMR SG_ 528 PROSHORT_CyclicCounter 0;
BA_REL_ "GenSigTimeoutTime" BU_SG_REL_ SCC SG_ 528 PROSHORT_CyclicCounter 0;
BA_REL_ "GenSigTimeoutTime" BU_SG_REL_ FR_CMR SG_ 528 PROSHORT_PathIndex 0;
BA_REL_ "GenSigTimeoutTime" BU_SG_REL_ SCC SG_ 528 PROSHORT_PathIndex 0;
BA_REL_ "GenSigTimeoutTime" BU_SG_REL_ FR_CMR SG_ 528 PROSHORT_Accuracy 0;
BA_REL_ "GenSigTimeoutTime" BU_SG_REL_ SCC SG_ 528 PROSHORT_Accuracy 0;
BA_REL_ "GenSigTimeoutTime" BU_SG_REL_ FR_CMR SG_ 528 PROSHORT_Distance 0;
BA_REL_ "GenSigTimeoutTime" BU_SG_REL_ SCC SG_ 528 PROSHORT_Distance 0;
BA_REL_ "GenSigTimeoutTime" BU_SG_REL_ FR_CMR SG_ 528 PROSHORT_Value0 0;
BA_REL_ "GenSigTimeoutTime" BU_SG_REL_ SCC SG_ 528 PROSHORT_Value0 0;
BA_REL_ "GenSigTimeoutTime" BU_SG_REL_ FR_CMR SG_ 528 PROSHORT_Value1 0;
BA_REL_ "GenSigTimeoutTime" BU_SG_REL_ SCC SG_ 528 PROSHORT_Value1 0;
BA_REL_ "GenSigTimeoutTime" BU_SG_REL_ FR_CMR SG_ 528 PROSHORT_ProfileType 0;
BA_REL_ "GenSigTimeoutTime" BU_SG_REL_ SCC SG_ 528 PROSHORT_ProfileType 0;
BA_REL_ "GenSigTimeoutTime" BU_SG_REL_ FR_CMR SG_ 528 PROSHORT_ControlPoint 0;
BA_REL_ "GenSigTimeoutTime" BU_SG_REL_ SCC SG_ 528 PROSHORT_ControlPoint 0;
BA_REL_ "GenSigTimeoutTime" BU_SG_REL_ FR_CMR SG_ 528 PROSHORT_Retransmission 0;
BA_REL_ "GenSigTimeoutTime" BU_SG_REL_ SCC SG_ 528 PROSHORT_Retransmission 0;
BA_REL_ "GenSigTimeoutTime" BU_SG_REL_ FR_CMR SG_ 528 PROSHORT_Update 0;
BA_REL_ "GenSigTimeoutTime" BU_SG_REL_ SCC SG_ 528 PROSHORT_Update 0;
BA_REL_ "GenSigTimeoutTime" BU_SG_REL_ FR_CMR SG_ 524 SEG_MessageType 0;
BA_REL_ "GenSigTimeoutTime" BU_SG_REL_ SCC SG_ 524 SEG_MessageType 0;
BA_REL_ "GenSigTimeoutTime" BU_SG_REL_ FR_CMR SG_ 524 SEG_Offset 0;
BA_REL_ "GenSigTimeoutTime" BU_SG_REL_ SCC SG_ 524 SEG_Offset 0;
BA_REL_ "GenSigTimeoutTime" BU_SG_REL_ FR_CMR SG_ 524 SEG_CyclicCounter 0;
BA_REL_ "GenSigTimeoutTime" BU_SG_REL_ SCC SG_ 524 SEG_CyclicCounter 0;
BA_REL_ "GenSigTimeoutTime" BU_SG_REL_ FR_CMR SG_ 524 SEG_PathIndex 0;
BA_REL_ "GenSigTimeoutTime" BU_SG_REL_ SCC SG_ 524 SEG_PathIndex 0;
BA_REL_ "GenSigTimeoutTime" BU_SG_REL_ FR_CMR SG_ 524 SEG_Tunnel 0;
BA_REL_ "GenSigTimeoutTime" BU_SG_REL_ SCC SG_ 524 SEG_Tunnel 0;
BA_REL_ "GenSigTimeoutTime" BU_SG_REL_ FR_CMR SG_ 524 SEG_Bridge 0;
BA_REL_ "GenSigTimeoutTime" BU_SG_REL_ SCC SG_ 524 SEG_Bridge 0;
BA_REL_ "GenSigTimeoutTime" BU_SG_REL_ FR_CMR SG_ 524 SEG_BuiltUpArea 0;
BA_REL_ "GenSigTimeoutTime" BU_SG_REL_ SCC SG_ 524 SEG_BuiltUpArea 0;
BA_REL_ "GenSigTimeoutTime" BU_SG_REL_ FR_CMR SG_ 524 SEG_Retransmission 0;
BA_REL_ "GenSigTimeoutTime" BU_SG_REL_ SCC SG_ 524 SEG_Retransmission 0;
BA_REL_ "GenSigTimeoutTime" BU_SG_REL_ FR_CMR SG_ 524 SEG_Update 0;
BA_REL_ "GenSigTimeoutTime" BU_SG_REL_ SCC SG_ 524 SEG_Update 0;
BA_REL_ "GenSigTimeoutTime" BU_SG_REL_ FR_CMR SG_ 524 SEG_RelativeProbability 0;
BA_REL_ "GenSigTimeoutTime" BU_SG_REL_ SCC SG_ 524 SEG_RelativeProbability 0;
BA_REL_ "GenSigTimeoutTime" BU_SG_REL_ FR_CMR SG_ 524 SEG_FunctionalRoadClass 0;
BA_REL_ "GenSigTimeoutTime" BU_SG_REL_ SCC SG_ 524 SEG_FunctionalRoadClass 0;
BA_REL_ "GenSigTimeoutTime" BU_SG_REL_ FR_CMR SG_ 524 SEG_CalculatedRoute 0;
BA_REL_ "GenSigTimeoutTime" BU_SG_REL_ SCC SG_ 524 SEG_CalculatedRoute 0;
BA_REL_ "GenSigTimeoutTime" BU_SG_REL_ FR_CMR SG_ 524 SEG_ComplexIntersection 0;
BA_REL_ "GenSigTimeoutTime" BU_SG_REL_ SCC SG_ 524 SEG_ComplexIntersection 0;
BA_REL_ "GenSigTimeoutTime" BU_SG_REL_ FR_CMR SG_ 524 SEG_FormOfWay 0;
BA_REL_ "GenSigTimeoutTime" BU_SG_REL_ SCC SG_ 524 SEG_FormOfWay 0;
BA_REL_ "GenSigTimeoutTime" BU_SG_REL_ FR_CMR SG_ 524 SEG_SpeedLimit 0;
BA_REL_ "GenSigTimeoutTime" BU_SG_REL_ SCC SG_ 524 SEG_SpeedLimit 0;
BA_REL_ "GenSigTimeoutTime" BU_SG_REL_ FR_CMR SG_ 524 SEG_SpeedLimitType 0;
BA_REL_ "GenSigTimeoutTime" BU_SG_REL_ SCC SG_ 524 SEG_SpeedLimitType 0;
BA_REL_ "GenSigTimeoutTime" BU_SG_REL_ FR_CMR SG_ 524 SEG_DividedRoad 0;
BA_REL_ "GenSigTimeoutTime" BU_SG_REL_ SCC SG_ 524 SEG_DividedRoad 0;
BA_REL_ "GenSigTimeoutTime" BU_SG_REL_ FR_CMR SG_ 524 SEG_OppositeLanes 0;
BA_REL_ "GenSigTimeoutTime" BU_SG_REL_ SCC SG_ 524 SEG_OppositeLanes 0;
BA_REL_ "GenSigTimeoutTime" BU_SG_REL_ FR_CMR SG_ 524 SEG_DirectionLanes 0;
BA_REL_ "GenSigTimeoutTime" BU_SG_REL_ SCC SG_ 524 SEG_DirectionLanes 0;
BA_REL_ "GenSigTimeoutTime" BU_SG_REL_ CGW SG_ 1371 AVM_View 2100;
BA_REL_ "GenSigTimeoutTime" BU_SG_REL_ CGW SG_ 1371 AVM_Display_Message 2100;
BA_REL_ "GenSigTimeoutTime" BU_SG_REL_ CGW SG_ 1371 AVM_Option 2100;
BA_REL_ "GenSigTimeoutTime" BU_SG_REL_ CGW SG_ 1371 AVM_Btn_Show 2100;
BA_REL_ "GenSigTimeoutTime" BU_SG_REL_ CGW SG_ 1371 AVM_HU_RearView_Option 2100;
BA_REL_ "GenSigTimeoutTime" BU_SG_REL_ CGW SG_ 1371 AVM_HU_FrontView_Option 2100;
BA_REL_ "GenSigTimeoutTime" BU_SG_REL_ CGW SG_ 1371 AVM_Version 2100;
BA_REL_ "GenSigTimeoutTime" BU_SG_REL_ FR_CMR SG_ 516 POS_MessageType 0;
BA_REL_ "GenSigTimeoutTime" BU_SG_REL_ SCC SG_ 516 POS_MessageType 0;
BA_REL_ "GenSigTimeoutTime" BU_SG_REL_ FR_CMR SG_ 516 POS_Offset 0;
BA_REL_ "GenSigTimeoutTime" BU_SG_REL_ SCC SG_ 516 POS_Offset 0;
BA_REL_ "GenSigTimeoutTime" BU_SG_REL_ FR_CMR SG_ 516 POS_CyclicCounter 0;
BA_REL_ "GenSigTimeoutTime" BU_SG_REL_ SCC SG_ 516 POS_CyclicCounter 0;
BA_REL_ "GenSigTimeoutTime" BU_SG_REL_ FR_CMR SG_ 516 POS_PathIndex 0;
BA_REL_ "GenSigTimeoutTime" BU_SG_REL_ SCC SG_ 516 POS_PathIndex 0;
BA_REL_ "GenSigTimeoutTime" BU_SG_REL_ FR_CMR SG_ 516 POS_PositionIndex 0;
BA_REL_ "GenSigTimeoutTime" BU_SG_REL_ SCC SG_ 516 POS_PositionIndex 0;
BA_REL_ "GenSigTimeoutTime" BU_SG_REL_ FR_CMR SG_ 516 POS_PositionProbability 0;
BA_REL_ "GenSigTimeoutTime" BU_SG_REL_ SCC SG_ 516 POS_PositionProbability 0;
BA_REL_ "GenSigTimeoutTime" BU_SG_REL_ FR_CMR SG_ 516 POS_PositionAge 0;
BA_REL_ "GenSigTimeoutTime" BU_SG_REL_ SCC SG_ 516 POS_PositionAge 0;
BA_REL_ "GenSigTimeoutTime" BU_SG_REL_ FR_CMR SG_ 516 POS_PositionConfidence 0;
BA_REL_ "GenSigTimeoutTime" BU_SG_REL_ SCC SG_ 516 POS_PositionConfidence 0;
BA_REL_ "GenSigTimeoutTime" BU_SG_REL_ FR_CMR SG_ 516 POS_CurrentLane 0;
BA_REL_ "GenSigTimeoutTime" BU_SG_REL_ SCC SG_ 516 POS_CurrentLane 0;
BA_REL_ "GenSigTimeoutTime" BU_SG_REL_ FR_CMR SG_ 516 POS_RangeAvgSpeed 0;
BA_REL_ "GenSigTimeoutTime" BU_SG_REL_ SCC SG_ 516 POS_RangeAvgSpeed 0;
BA_REL_ "GenSigTimeoutTime" BU_SG_REL_ FR_CMR SG_ 516 POS_RelativeHeading 0;
BA_REL_ "GenSigTimeoutTime" BU_SG_REL_ SCC SG_ 516 POS_RelativeHeading 0;
BA_REL_ "GenSigTimeoutTime" BU_SG_REL_ FR_CMR SG_ 532 PROLONG_Value 0;
BA_REL_ "GenSigTimeoutTime" BU_SG_REL_ SCC SG_ 532 PROLONG_Value 0;
BA_REL_ "GenSigTimeoutTime" BU_SG_REL_ FR_CMR SG_ 532 PROLONG_MessageType 0;
BA_REL_ "GenSigTimeoutTime" BU_SG_REL_ SCC SG_ 532 PROLONG_MessageType 0;
BA_REL_ "GenSigTimeoutTime" BU_SG_REL_ FR_CMR SG_ 532 PROLONG_Offset 0;
BA_REL_ "GenSigTimeoutTime" BU_SG_REL_ SCC SG_ 532 PROLONG_Offset 0;
BA_REL_ "GenSigTimeoutTime" BU_SG_REL_ FR_CMR SG_ 532 PROLONG_CyclicCounter 0;
BA_REL_ "GenSigTimeoutTime" BU_SG_REL_ SCC SG_ 532 PROLONG_CyclicCounter 0;
BA_REL_ "GenSigTimeoutTime" BU_SG_REL_ FR_CMR SG_ 532 PROLONG_PathIndex 0;
BA_REL_ "GenSigTimeoutTime" BU_SG_REL_ SCC SG_ 532 PROLONG_PathIndex 0;
BA_REL_ "GenSigTimeoutTime" BU_SG_REL_ FR_CMR SG_ 532 PROLONG_ProfileType 0;
BA_REL_ "GenSigTimeoutTime" BU_SG_REL_ SCC SG_ 532 PROLONG_ProfileType 0;
BA_REL_ "GenSigTimeoutTime" BU_SG_REL_ FR_CMR SG_ 532 PROLONG_CountrolPoint 0;
BA_REL_ "GenSigTimeoutTime" BU_SG_REL_ SCC SG_ 532 PROLONG_CountrolPoint 0;
BA_REL_ "GenSigTimeoutTime" BU_SG_REL_ FR_CMR SG_ 532 PROLONG_Retransmission 0;
BA_REL_ "GenSigTimeoutTime" BU_SG_REL_ SCC SG_ 532 PROLONG_Retransmission 0;
BA_REL_ "GenSigTimeoutTime" BU_SG_REL_ FR_CMR SG_ 532 PROLONG_Update 0;
BA_REL_ "GenSigTimeoutTime" BU_SG_REL_ SCC SG_ 532 PROLONG_Update 0;
BA_REL_ "GenSigTimeoutTime" BU_SG_REL_ FR_CMR SG_ 520 META_MessageType 0;
BA_REL_ "GenSigTimeoutTime" BU_SG_REL_ SCC SG_ 520 META_MessageType 0;
BA_REL_ "GenSigTimeoutTime" BU_SG_REL_ FR_CMR SG_ 520 META_MapProvider 0;
BA_REL_ "GenSigTimeoutTime" BU_SG_REL_ SCC SG_ 520 META_MapProvider 0;
BA_REL_ "GenSigTimeoutTime" BU_SG_REL_ FR_CMR SG_ 520 META_CountryCode 0;
BA_REL_ "GenSigTimeoutTime" BU_SG_REL_ SCC SG_ 520 META_CountryCode 0;
BA_REL_ "GenSigTimeoutTime" BU_SG_REL_ FR_CMR SG_ 520 META_CyclicCounter 0;
BA_REL_ "GenSigTimeoutTime" BU_SG_REL_ SCC SG_ 520 META_CyclicCounter 0;
BA_REL_ "GenSigTimeoutTime" BU_SG_REL_ FR_CMR SG_ 520 META_MajorProtocolVersion 0;
BA_REL_ "GenSigTimeoutTime" BU_SG_REL_ SCC SG_ 520 META_MajorProtocolVersion 0;
BA_REL_ "GenSigTimeoutTime" BU_SG_REL_ FR_CMR SG_ 520 META_MinorProtocolSubVer 0;
BA_REL_ "GenSigTimeoutTime" BU_SG_REL_ SCC SG_ 520 META_MinorProtocolSubVer 0;
BA_REL_ "GenSigTimeoutTime" BU_SG_REL_ FR_CMR SG_ 520 META_HardwareVersion 0;
BA_REL_ "GenSigTimeoutTime" BU_SG_REL_ SCC SG_ 520 META_HardwareVersion 0;
BA_REL_ "GenSigTimeoutTime" BU_SG_REL_ FR_CMR SG_ 520 META_DrivingSide 0;
BA_REL_ "GenSigTimeoutTime" BU_SG_REL_ SCC SG_ 520 META_DrivingSide 0;
BA_REL_ "GenSigTimeoutTime" BU_SG_REL_ FR_CMR SG_ 520 META_RegionCode 0;
BA_REL_ "GenSigTimeoutTime" BU_SG_REL_ SCC SG_ 520 META_RegionCode 0;
BA_REL_ "GenSigTimeoutTime" BU_SG_REL_ FR_CMR SG_ 520 META_MapVersionQuarter 0;
BA_REL_ "GenSigTimeoutTime" BU_SG_REL_ SCC SG_ 520 META_MapVersionQuarter 0;
BA_REL_ "GenSigTimeoutTime" BU_SG_REL_ FR_CMR SG_ 520 META_MapVersionYear 0;
BA_REL_ "GenSigTimeoutTime" BU_SG_REL_ SCC SG_ 520 META_MapVersionYear 0;
BA_REL_ "GenSigTimeoutTime" BU_SG_REL_ FR_CMR SG_ 520 META_SpeedUnit 0;
BA_REL_ "GenSigTimeoutTime" BU_SG_REL_ SCC SG_ 520 META_SpeedUnit 0;
BA_REL_ "GenSigTimeoutTime" BU_SG_REL_ FR_CMR SG_ 520 META_MinorProtocolVersion 0;
BA_REL_ "GenSigTimeoutTime" BU_SG_REL_ SCC SG_ 520 META_MinorProtocolVersion 0;
BA_REL_ "GenSigTimeoutTime" BU_SG_REL_ AVM SG_ 1363 CF_Gway_ExtTailAct 1000;
BA_REL_ "GenSigTimeoutTime" BU_SG_REL_ BCW SG_ 1363 CF_Gway_ExtTailAct 1000;
BA_REL_ "GenSigTimeoutTime" BU_SG_REL_ CLU SG_ 1363 CF_Gway_ExtTailAct 1000;
BA_REL_ "GenSigTimeoutTime" BU_SG_REL_ HUD SG_ 1363 CF_Gway_ExtTailAct 1000;
BA_REL_ "GenSigTimeoutTime" BU_SG_REL_ CLU SG_ 1363 CF_Gway_AvTail 1000;
BA_REL_ "GenSigTimeoutTime" BU_SG_REL_ CLU SG_ 1363 CF_Gway_RearFogAct 1000;
BA_REL_ "GenSigTimeoutTime" BU_SG_REL_ CLU SG_ 1363 CF_Gway_RRDrSw 1000;
BA_REL_ "GenSigTimeoutTime" BU_SG_REL_ CLU SG_ 1363 CF_Gway_RLDrSw 1000;
BA_REL_ "GenSigTimeoutTime" BU_SG_REL_ CLU SG_ 1363 CF_Gway_IntTailAct 1000;
BA_REL_ "GenSigTimeoutTime" BU_SG_REL_ FR_CMR SG_ 1363 CF_Gway_WiperParkPosition 1000;
BA_REL_ "GenSigTimeoutTime" BU_SG_REL_ CLU SG_ 1363 CF_Gway_ESCLNotLockedWarn 1000;
BA_REL_ "GenSigTimeoutTime" BU_SG_REL_ CLU SG_ 1363 CF_Gway_IDoutWarn 1000;
BA_REL_ "GenSigTimeoutTime" BU_SG_REL_ CLU SG_ 1363 CF_Gway_ImmoLp 1000;
BA_REL_ "GenSigTimeoutTime" BU_SG_REL_ CLU SG_ 1363 CF_Gway_VehicleNotPWarn 1000;
BA_REL_ "GenSigTimeoutTime" BU_SG_REL_ CLU SG_ 1363 CF_Gway_DeactivationWarn 1000;
BA_REL_ "GenSigTimeoutTime" BU_SG_REL_ CLU SG_ 1363 CF_Gway_KeyBATDischargeWarn 1000;
BA_REL_ "GenSigTimeoutTime" BU_SG_REL_ CLU SG_ 1363 CF_Gway_SJBDeliveryMode 1000;
BA_REL_ "GenSigTimeoutTime" BU_SG_REL_ CLU SG_ 1363 CF_Gway_SMKDispWarn 1000;
BA_REL_ "GenSigTimeoutTime" BU_SG_REL_ AFS SG_ 688 SAS_Angle 100;
BA_REL_ "GenSigTimeoutTime" BU_SG_REL_ AVM SG_ 688 SAS_Angle 100;
BA_REL_ "GenSigTimeoutTime" BU_SG_REL_ CGW SG_ 688 SAS_Angle 100;
BA_REL_ "GenSigTimeoutTime" BU_SG_REL_ ECS SG_ 688 SAS_Angle 100;
BA_REL_ "GenSigTimeoutTime" BU_SG_REL_ ESC SG_ 688 SAS_Angle 100;
BA_REL_ "GenSigTimeoutTime" BU_SG_REL_ FR_RDR SG_ 688 SAS_Angle 100;
BA_REL_ "GenSigTimeoutTime" BU_SG_REL_ FR_CMR SG_ 688 SAS_Angle 100;
BA_REL_ "GenSigTimeoutTime" BU_SG_REL_ MDPS SG_ 688 SAS_Angle 100;
BA_REL_ "GenSigTimeoutTime" BU_SG_REL_ RVM SG_ 688 SAS_Angle 100;
BA_REL_ "GenSigTimeoutTime" BU_SG_REL_ SCC SG_ 688 SAS_Angle 100;
BA_REL_ "GenSigTimeoutTime" BU_SG_REL_ AFS SG_ 688 SAS_Speed 100;
BA_REL_ "GenSigTimeoutTime" BU_SG_REL_ CGW SG_ 688 SAS_Speed 100;
BA_REL_ "GenSigTimeoutTime" BU_SG_REL_ ECS SG_ 688 SAS_Speed 100;
BA_REL_ "GenSigTimeoutTime" BU_SG_REL_ ESC SG_ 688 SAS_Speed 100;
BA_REL_ "GenSigTimeoutTime" BU_SG_REL_ FR_RDR SG_ 688 SAS_Speed 100;
BA_REL_ "GenSigTimeoutTime" BU_SG_REL_ FR_CMR SG_ 688 SAS_Speed 100;
BA_REL_ "GenSigTimeoutTime" BU_SG_REL_ MDPS SG_ 688 SAS_Speed 100;
BA_REL_ "GenSigTimeoutTime" BU_SG_REL_ SCC SG_ 688 SAS_Speed 100;
BA_REL_ "GenSigTimeoutTime" BU_SG_REL_ CGW SG_ 688 SAS_Stat 100;
BA_REL_ "GenSigTimeoutTime" BU_SG_REL_ ECS SG_ 688 SAS_Stat 100;
BA_REL_ "GenSigTimeoutTime" BU_SG_REL_ ESC SG_ 688 SAS_Stat 100;
BA_REL_ "GenSigTimeoutTime" BU_SG_REL_ FR_RDR SG_ 688 SAS_Stat 100;
BA_REL_ "GenSigTimeoutTime" BU_SG_REL_ FR_CMR SG_ 688 SAS_Stat 100;
BA_REL_ "GenSigTimeoutTime" BU_SG_REL_ MDPS SG_ 688 SAS_Stat 100;
BA_REL_ "GenSigTimeoutTime" BU_SG_REL_ SCC SG_ 688 SAS_Stat 100;
BA_REL_ "GenSigTimeoutTime" BU_SG_REL_ CGW SG_ 688 MsgCount 100;
BA_REL_ "GenSigTimeoutTime" BU_SG_REL_ ECS SG_ 688 MsgCount 100;
BA_REL_ "GenSigTimeoutTime" BU_SG_REL_ ESC SG_ 688 MsgCount 100;
BA_REL_ "GenSigTimeoutTime" BU_SG_REL_ FR_RDR SG_ 688 MsgCount 100;
BA_REL_ "GenSigTimeoutTime" BU_SG_REL_ FR_CMR SG_ 688 MsgCount 100;
BA_REL_ "GenSigTimeoutTime" BU_SG_REL_ MDPS SG_ 688 MsgCount 100;
BA_REL_ "GenSigTimeoutTime" BU_SG_REL_ SCC SG_ 688 MsgCount 100;
BA_REL_ "GenSigTimeoutTime" BU_SG_REL_ CGW SG_ 688 CheckSum 100;
BA_REL_ "GenSigTimeoutTime" BU_SG_REL_ ECS SG_ 688 CheckSum 100;
BA_REL_ "GenSigTimeoutTime" BU_SG_REL_ ESC SG_ 688 CheckSum 100;
BA_REL_ "GenSigTimeoutTime" BU_SG_REL_ FR_RDR SG_ 688 CheckSum 100;
BA_REL_ "GenSigTimeoutTime" BU_SG_REL_ FR_CMR SG_ 688 CheckSum 100;
BA_REL_ "GenSigTimeoutTime" BU_SG_REL_ MDPS SG_ 688 CheckSum 100;
BA_REL_ "GenSigTimeoutTime" BU_SG_REL_ SCC SG_ 688 CheckSum 100;
BA_REL_ "GenSigTimeoutTime" BU_SG_REL_ AFS SG_ 1345 CF_Gway_LightSwState 1000;
BA_REL_ "GenSigTimeoutTime" BU_SG_REL_ CLU SG_ 1345 CF_Gway_LightSwState 1000;
BA_REL_ "GenSigTimeoutTime" BU_SG_REL_ FR_CMR SG_ 1345 CF_Gway_TSigRHSw 1000;
BA_REL_ "GenSigTimeoutTime" BU_SG_REL_ FR_CMR SG_ 1345 CF_Gway_TSigLHSw 1000;
BA_REL_ "GenSigTimeoutTime" BU_SG_REL_ CLU SG_ 1345 CF_Gway_PassiveAccessLock 1000;
BA_REL_ "GenSigTimeoutTime" BU_SG_REL_ CLU SG_ 1345 CF_Gway_PassiveAccessUnlock 1000;
BA_REL_ "GenSigTimeoutTime" BU_SG_REL_ CLU SG_ 1345 C_SunRoofOpenState 1000;
BA_REL_ "GenSigTimeoutTime" BU_SG_REL_ AVM SG_ 1407 HU_Type 3500;
BA_REL_ "GenSigTimeoutTime" BU_SG_REL_ FR_CMR SG_ 1407 HU_Type 3500;
BA_REL_ "GenSigTimeoutTime" BU_SG_REL_ RVM SG_ 1407 HU_Type 3500;
BA_REL_ "GenSigTimeoutTime" BU_SG_REL_ FR_CMR SG_ 1407 HU_DistributeInfo 3500;
BA_REL_ "GenSigTimeoutTime" BU_SG_REL_ SCC SG_ 1407 HU_DistributeInfo 3500;
BA_REL_ "GenSigTimeoutTime" BU_SG_REL_ FR_CMR SG_ 1407 HU_AdasSupport 3500;
BA_REL_ "GenSigTimeoutTime" BU_SG_REL_ SCC SG_ 1407 HU_AdasSupport 3500;
BA_REL_ "GenSigTimeoutTime" BU_SG_REL_ AVM SG_ 1397 HU_AVM_Cal_Cmd 0;
BA_REL_ "GenSigTimeoutTime" BU_SG_REL_ AVM SG_ 1397 HU_AVM_PT_X 0;
BA_REL_ "GenSigTimeoutTime" BU_SG_REL_ AVM SG_ 1397 HU_AVM_PT_Y 0;
BA_REL_ "GenSigTimeoutTime" BU_SG_REL_ AVM SG_ 1397 HU_AVM_SelectedMenu 0;
BA_REL_ "GenSigTimeoutTime" BU_SG_REL_ AVM SG_ 1397 HU_AVM_CameraOff 0;
BA_REL_ "GenSigTimeoutTime" BU_SG_REL_ AVM SG_ 1397 HU_AVM_Option 0;
BA_REL_ "GenSigTimeoutTime" BU_SG_REL_ AVM SG_ 1397 HU_AVM_RearView_Option 0;
BA_REL_ "GenSigTimeoutTime" BU_SG_REL_ AVM SG_ 1397 HU_AVM_FrontView_Option 0;
VAL_ 3221225472 ISLA_OptUsmSta 7 "Invalid (GRAY)" 6 "Reserved" 5 "Reserved" 4 "Reserved" 3 "Assist" 2 "Warning" 1 "Off" 0 "None ISLA Option" ;
VAL_ 3221225472 FRM_FORMAT 2 "Single frame " ;
VAL_ 3221225472 SID 40 "Disable transmission of normal CAN messages. (Stop normal CAN communication)" 41 "Enable transmission of normal CAN messages. (Resume normal CAN communication)" ;
VAL_ 3221225472 REQ_RESPONSE 0 "Reserved" 1 "Response required" 2 "No response required" ;
VAL_ 1183 Navi_ISLW_TunnelExist 3 "Invalid" 2 "Reserved" 1 "Exist" 0 "None" ;
VAL_ 1183 Navi_ISLW_TimeSpd 255 "Invalid" 254 "Unlimited" 0 "None" ;
VAL_ 1183 Navi_ISLW_WeatherInfo 7 "Invalid" 6 "Reserved" 5 "Reserved" 4 "Reserved" 3 "Snow_Rain" 2 "Snow" 1 "Rain" 0 "None" ;
VAL_ 1183 Navi_ISLW_BUAInfo 3 "Invalid" 2 "BUA Exit" 1 "BUA Entrance" 0 "None" ;
VAL_ 1183 Navi_ISLW_TollExist 3 "Invalid" 2 "Elect Toll" 1 "Normal Toll" 0 "None" ;
VAL_ 1260 ISLA_AddtnlSign 28 "Winding Road" 27 "Left Curve" 26 "Right Curve" 25 "Roundabout" 24 "Exit" 16 "Do Not Pass" 13 "Lane Reduction" 12 "Road Construction Ahead" 11 "Yield Ahead" 10 "Stop Ahead" 9 "Yield" 8 "Stop" 3 "Bicycle Crossing" 2 "Pedestrian Crossing" 1 "School Crossing" 0 "No Recognition (default)" ;
VAL_ 1260 ISLA_SchoolZone 1 "School Zone" 0 "No School Zone" ;
VAL_ 1260 ISLA_Cntry 15 "Initial Value (default)" 14 "Reserved" 13 "Reserved" 12 "Reserved" 11 "Reserved" 10 "Reserved" 9 "Reserved" 8 "Reserved" 7 "Reserved" 6 "Reserved" 5 "Australia" 4 "Canada" 3 "USA" 2 "China" 1 "Domestic" 0 "Europe/Russia/Australia" ;
VAL_ 1260 ISLA_Popup 7 "Reserved" 6 "Reserved" 5 "Reserved" 4 "CC_SCC Speed has Changed" 3 "CC_SCC Speed will Change" 2 "MSLA Speed has Changed" 1 "MSLA Speed will Change" 0 "No Popup" ;
VAL_ 1260 ISLA_AutoUsmSta 3 "Invalid (GRAY)" 2 "Auto On" 1 "Auto Off" 0 "None Auto Function" ;
VAL_ 1260 ISLA_OffstUsmSta 7 "Invalid (GRAY)" 6 "Reserved" 5 "+10kph or +5mph" 4 "+5kph or +3mph" 3 "0kph or 0mph" 2 "-5kph or -3mph" 1 "-10kph or -5mph" 0 "None Offset Function" ;
VAL_ 1260 CF_ISLW_Spd_Dis_NAVI_Con2 255 "Invalid" 254 "RHD Conditional No Passing ZONE" 253 "LHD Conditional No Passing ZONE" 1 "1~252 (PH)=1*(HEX) [KPH or MPH]" 0 "No Recognition (Default)" ;
VAL_ 1260 CF_ISLW_Spd_Dis_NAVI_Con1 255 "Invalid" 254 "RHD Conditional No Passing ZONE" 253 "LHD Conditional No Passing ZONE" 1 "1~252 (PH)=1*(HEX) [KPH or MPH]" 0 "No Recognition (Default)" ;
VAL_ 1260 CF_ISLW_Spd_Dis_CLU_Con2 255 "Invalid" 254 ":RHD Conditional No Passing ZONE" 253 "LHD Conditional No Passing ZONE" 1 "1~252 (PH)=1*(HEX) [KPH or MPH]" 0 "No Recognition (Default)" ;
VAL_ 1260 CF_ISLW_Spd_Dis_CLU_Con1 255 "Invalid" 254 "RHD Conditional No Passing ZONE" 253 "LHD Conditional No Passing ZONE" 1 "1~252 (PH)=1*(HEX) [KPH or MPH]" 0 "No Recognition (Default)" ;
VAL_ 1260 CF_ISLW_ConInfo_Sta_Con2 15 "Reserved" 14 "Generic" 13 "Reserved" 12 "Reserved" 11 "Reserved" 10 "Reserved" 9 "Reserved" 8 "Reserved" 7 "Reserved" 6 "Reserved" 5 "Reserved" 4 "Trailer" 3 "Snow, Rain" 2 "Snow" 1 "Rain" 0 "None (Default)" ;
VAL_ 1260 CF_ISLW_ConInfo_Sta_Con1 15 "Reserved" 14 "Generic" 13 "Reserved" 12 "Reserved" 11 "Reserved" 10 "Reserved" 9 "Reserved" 8 "Reserved" 7 "Reserved" 6 "Reserved" 5 "Reserved" 4 "Trailer" 3 "Snow, Rain" 2 "Snow" 1 "Rain" 0 "None (Default)" ;
VAL_ 1260 ISLA_OptUsmSta 7 "Invalid (GRAY)" 6 "Reserved" 5 "Reserved" 4 "Reserved" 3 "Assist" 2 "Warning" 1 "Off" 0 "None ISLA Option" ;
VAL_ 1155 FCA_WarningTargetDisplay 14 "Reserved" 13 "Reserved" 12 "FCA-JT(R)" 11 "FCA-JT(L)" 10 "Reserved" 9 "Reserved" 8 "FCA-JC(R)" 7 "FCA-JC(L)" 6 "Reserved" 5 "Reserved" 4 "Reserved" 3 "Reserved" 2 "Reserved" 1 "FCA" 0 "None" ;
VAL_ 1155 FCA_DrvSetState 7 "Invalid" 6 "Reserved" 5 "Reserved" 4 "Reserved" 3 "Early" 2 "Normal" 1 "Late" 0 "Default" ;
VAL_ 1155 FCA_USM 7 "Invalid" 6 "Reserved" 5 "Reserved" 4 "Reserved" 3 "Assist" 2 "Warning" 1 "Off" 0 "Default" ;
VAL_ 1190 CF_AVN_NSCCCamNValueSet 3 "Invalid" 2 "Enable" 1 "Disable" 0 "Default" ;
VAL_ 1190 CF_AVN_SCCDrvModeNValueSet 7 "Invalid" 6 "Reserved" 5 "Reserved" 4 "Reserved" 3 "Dynamic" 2 "Normal" 1 "Comfort" 0 "Default" ;
VAL_ 1190 CF_Clu_DawResetReq 1 "ResetReq" 0 "Default" ;
VAL_ 1190 CF_AVN_DAWModeNValueSet_New 3 "Invalid" 2 "On" 1 "Off" 0 "Default" ;
VAL_ 1190 CF_AVN_HBANValueSet 3 "Invalid" 2 "HBA On" 1 "HBA Off" 0 "Default(NoneHBA)" ;
VAL_ 1190 CF_AVN_LkaModeNValueSet 7 "Invalid" 6 "LDW/LKA OFF" 5 "LDW only OFF (None LKA)" 4 "LDW only ON (None LKA)" 3 "ACTIVE LKA" 2 "LKA mode" 1 "LDW mode" 0 "Default" ;
VAL_ 1190 CF_AVN_LVDANValueSet 3 "Invalid" 2 "On" 1 "Off" 0 "Default" ;
VAL_ 1190 CF_AVN_WarningTimingNValueSet 7 "Invalid" 6 "Reserved" 5 "Reserved" 4 "Reserved" 3 "Reserved" 2 "LKA Mode" 1 "LDW Mode" 0 "Default" ;
VAL_ 1190 CF_AVN_CluUSMReset 1 "Reset" 0 "Default" ;
VAL_ 1190 CF_AVN_FCANValueSet 7 "Invalid" 5 "Reserved" 6 "Reserved" 4 "Reserved" 3 "Assist" 2 "Warning" 1 "Off" 0 "Default(NoneFCA)" ;
VAL_ 550 STUB_MessageType 0 "Reserved" 1 "Position" 2 "Segment" 3 "Stub" 4 "Profile Short" 5 "Profile Long" 6 "Meta Data" 7 "Invalid" ;
VAL_ 550 STUB_Offset 8191 "Invalid" ;
VAL_ 550 STUB_CyclicCounter 0 "Cyclic Counter" 1 "Cyclic Counter" 2 "Cyclic Counter" 3 "Cyclic Counter" ;
VAL_ 550 STUB_PathIndex 0 "first path in the Horizon" 1 "Reserved" 2 "Reserved" 3 "Reserved" 4 "Reserved" 5 "Reserved" 6 "Reserved" 7 "Reserved" 8 "General Path Index" 9 "General Path Index" 10 "General Path Index" 11 "General Path Index" 12 "General Path Index" 13 "General Path Index" 14 "General Path Index" 15 "General Path Index" 16 "General Path Index" 17 "General Path Index" 18 "General Path Index" 19 "General Path Index" 20 "General Path Index" 21 "General Path Index" 22 "General Path Index" 23 "General Path Index" 24 "General Path Index" 25 "General Path Index" 26 "General Path Index" 27 "General Path Index" 28 "General Path Index" 29 "General Path Index" 30 "General Path Index" 31 "General Path Index" 32 "General Path Index" 33 "General Path Index" 34 "General Path Index" 35 "General Path Index" 36 "General Path Index" 37 "General Path Index" 38 "General Path Index" 39 "General Path Index" 40 "General Path Index" 41 "General Path Index" 42 "General Path Index" 43 "General Path Index" 44 "General Path Index" 45 "General Path Index" 46 "General Path Index" 47 "General Path Index" 48 "General Path Index" 49 "General Path Index" 50 "General Path Index" 51 "General Path Index" 52 "General Path Index" 53 "General Path Index" 54 "General Path Index" 55 "General Path Index" 56 "General Path Index" 57 "General Path Index" 58 "General Path Index" 59 "General Path Index" 60 "General Path Index" 61 "General Path Index" 62 "General Path Index" 63 "General Path Index" ;
VAL_ 550 STUB_SubPathIndex 0 "Unknown" 1 "Reserved" 2 "Reserved" 3 "Reserved" 4 "Reserved" 5 "Reserved" 6 "Reserved" 7 "Reserved" 8 "General Path Index" 9 "General Path Index" 10 "General Path Index" 11 "General Path Index" 12 "General Path Index" 13 "General Path Index" 14 "General Path Index" 15 "General Path Index" 16 "General Path Index" 17 "General Path Index" 18 "General Path Index" 19 "General Path Index" 20 "General Path Index" 21 "General Path Index" 22 "General Path Index" 23 "General Path Index" 24 "General Path Index" 25 "General Path Index" 26 "General Path Index" 27 "General Path Index" 28 "General Path Index" 29 "General Path Index" 30 "General Path Index" 31 "General Path Index" 32 "General Path Index" 33 "General Path Index" 34 "General Path Index" 35 "General Path Index" 36 "General Path Index" 37 "General Path Index" 38 "General Path Index" 39 "General Path Index" 40 "General Path Index" 41 "General Path Index" 42 "General Path Index" 43 "General Path Index" 44 "General Path Index" 45 "General Path Index" 46 "General Path Index" 47 "General Path Index" 48 "General Path Index" 49 "General Path Index" 50 "General Path Index" 51 "General Path Index" 52 "General Path Index" 53 "General Path Index" 54 "General Path Index" 55 "General Path Index" 56 "General Path Index" 57 "General Path Index" 58 "General Path Index" 59 "General Path Index" 60 "General Path Index" 61 "General Path Index" 62 "General Path Index" 63 "General Path Index" ;
VAL_ 550 STUB_Retransmission 0 "False" 1 "True" ;
VAL_ 550 STUB_Update 0 "False" 1 "True" ;
VAL_ 550 STUB_RelativeProbability 0 "Turn not allowed" 1 "Relative probability" 2 "Relative probability" 3 "Relative probability" 4 "Relative probability" 5 "Relative probability" 6 "Relative probability" 7 "Relative probability" 8 "Relative probability" 9 "Relative probability" 10 "Relative probability" 11 "Relative probability" 12 "Relative probability" 13 "Relative probability" 14 "Relative probability" 15 "Relative probability" 16 "Relative probability" 17 "Relative probability" 18 "Relative probability" 19 "Relative probability" 20 "Relative probability" 21 "Relative probability" 22 "Relative probability" 23 "Relative probability" 24 "Relative probability" 25 "Relative probability" 26 "Relative probability" 27 "Relative probability" 28 "Relative probability" 29 "Relative probability" 30 "Relative probability" 31 "Invalid" ;
VAL_ 550 STUB_FunctionalRoadClass 0 "Unknown" 1 "Freeway" 2 "Arterial(City freeway)" 3 "County" 4 "Collector" 5 "Local" 6 "Etc(ferry unpaved)" 7 "Invalid" ;
VAL_ 550 STUB_CalculatedRoute 0 "Not Calculated Route(MPP)" 1 "Part of Calculated Route" 2 "Off Route or Recalculating Route" 3 "Invalid" ;
VAL_ 550 STUB_ComplexIntersection 0 "Not part of complex intersection" 1 "Part of of complex intersection" 2 "Unknown" 3 "Invalid" ;
VAL_ 550 STUB_FormOfWay 0 "Unknown" 1 "Main path(nondisjunction)" 2 "Main path(disjunction)" 3 "JC" 4 "Plural Junction M" 5 "IC" 6 "Reserved" 7 "Service Area" 8 "Reserved" 9 "Roundabout" 10 "P turn" 11 "U trun" 12 "Pedestrian" 13 "Frontage Road" 14 "Intersection internal" 15 "Invalid" ;
VAL_ 550 STUB_TurnAngle 0 "In path direction" 1 "1.417 degrees right" 126 "178.583 degrees right" 127 "Opposite direction" 128 "178.583 degrees left" 253 "1.417 degrees left" 254 "Unknown" 255 "Invalid" ;
VAL_ 550 STUB_LastStubAtOffset 0 "more STUB messages will be sent" 1 "last one of given parent" ;
VAL_ 550 STUB_RightOfWay 0 "Parent path has right of way" 1 "Sub-path has right of way" 2 "Unknown" 3 "Invalid" ;
VAL_ 550 STUB_OppositeLanes 0 "Unknown" 1 "One lane only" 2 "2 or more lanes" 3 "Invalid" ;
VAL_ 550 STUB_DirectionLanes 0 "Unknown" 1 "Lane count" 2 "Lane count" 3 "Lane count" 4 "Lane count" 5 "Lane count" 6 "6 or more lanes" 7 "Invalid" ;
VAL_ 528 PROSHORT_MessageType 0 "Reserved" 1 "Position" 2 "Segment" 3 "Stub" 4 "Profile Short" 5 "Profile Long" 6 "Meta Data" 7 "Invalid" ;
VAL_ 528 PROSHORT_Offset 8191 "Invalid" ;
VAL_ 528 PROSHORT_CyclicCounter 0 "Cyclic Counter" 1 "Cyclic Counter" 2 "Cyclic Counter" 3 "Cyclic Counter" ;
VAL_ 528 PROSHORT_PathIndex 0 "Unknown" 1 "Reserved" 2 "Reserved" 3 "Reserved" 4 "Reserved" 5 "Reserved" 6 "Reserved" 7 "Reserved" 8 "General Path Index" 9 "General Path Index" 10 "General Path Index" 11 "General Path Index" 12 "General Path Index" 13 "General Path Index" 14 "General Path Index" 15 "General Path Index" 16 "General Path Index" 17 "General Path Index" 18 "General Path Index" 19 "General Path Index" 20 "General Path Index" 21 "General Path Index" 22 "General Path Index" 23 "General Path Index" 24 "General Path Index" 25 "General Path Index" 26 "General Path Index" 27 "General Path Index" 28 "General Path Index" 29 "General Path Index" 30 "General Path Index" 31 "General Path Index" 32 "General Path Index" 33 "General Path Index" 34 "General Path Index" 35 "General Path Index" 36 "General Path Index" 37 "General Path Index" 38 "General Path Index" 39 "General Path Index" 40 "General Path Index" 41 "General Path Index" 42 "General Path Index" 43 "General Path Index" 44 "General Path Index" 45 "General Path Index" 46 "General Path Index" 47 "General Path Index" 48 "General Path Index" 49 "General Path Index" 50 "General Path Index" 51 "General Path Index" 52 "General Path Index" 53 "General Path Index" 54 "General Path Index" 55 "General Path Index" 56 "General Path Index" 57 "General Path Index" 58 "General Path Index" 59 "General Path Index" 60 "General Path Index" 61 "General Path Index" 62 "General Path Index" 63 "General Path Index" ;
VAL_ 528 PROSHORT_Accuracy 0 "High Accuracy" 1 "Middle Accuracy" 2 "Low Accuracy" 3 "Unknown" ;
VAL_ 528 PROSHORT_Distance 1023 "Invalid" ;
VAL_ 528 PROSHORT_Value0 1023 "Invalid" ;
VAL_ 528 PROSHORT_Value1 1023 "Invalid" ;
VAL_ 528 PROSHORT_ProfileType 0 "Invalid" 1 "Curvature" 2 "Route Number types" 3 "Slope(step)" 4 "Slope(Linear)" 5 "Road Accessibility" 6 "Road condition" 7 "Variable Speed Sign Position" 8 "Heading Change" 9 "Reserved for standard type" 10 "Reserved for standard type" 11 "Reserved for standard type" 12 "Reserved for standard type" 13 "Reserved for standard type" 14 "Reserved for standard type" 15 "Reserved for standard type" 16 "Alert Information Section" 17 "Curvature Average Speed" 18 "Reserved for system specific types" 19 "Reserved for system specific types" 20 "Reserved for system specific types" 21 "Reserved for system specific types" 22 "Reserved for system specific types" 23 "Reserved for system specific types" 24 "Reserved for system specific types" 25 "Reserved for system specific types" 26 "Reserved for system specific types" 27 "Reserved for system specific types" 28 "Reserved for system specific types" 29 "Reserved for system specific types" 30 "Reserved for system specific types" 31 "Reserved for system specific types" ;
VAL_ 528 PROSHORT_ControlPoint 0 "False" 1 "True" ;
VAL_ 528 PROSHORT_Retransmission 0 "False" 1 "True" ;
VAL_ 528 PROSHORT_Update 0 "False" 1 "True" ;
VAL_ 524 SEG_MessageType 0 "Reserved" 1 "Position" 2 "Segment" 3 "Stub" 4 "Profile Short" 5 "Profile Long" 6 "Meta Data" 7 "Invalid" ;
VAL_ 524 SEG_Offset 8191 "Invalid" ;
VAL_ 524 SEG_CyclicCounter 0 "Cyclic Counter" 1 "Cyclic Counter" 2 "Cyclic Counter" 3 "Cyclic Counter" ;
VAL_ 524 SEG_PathIndex 0 "Unknown" 1 "Reserved" 2 "Reserved" 3 "Reserved" 4 "Reserved" 5 "Reserved" 6 "Reserved" 7 "Reserved" 8 "General Path Index" 9 "General Path Index" 10 "General Path Index" 11 "General Path Index" 12 "General Path Index" 13 "General Path Index" 14 "General Path Index" 15 "General Path Index" 16 "General Path Index" 17 "General Path Index" 18 "General Path Index" 19 "General Path Index" 20 "General Path Index" 21 "General Path Index" 22 "General Path Index" 23 "General Path Index" 24 "General Path Index" 25 "General Path Index" 26 "General Path Index" 27 "General Path Index" 28 "General Path Index" 29 "General Path Index" 30 "General Path Index" 31 "General Path Index" 32 "General Path Index" 33 "General Path Index" 34 "General Path Index" 35 "General Path Index" 36 "General Path Index" 37 "General Path Index" 38 "General Path Index" 39 "General Path Index" 40 "General Path Index" 41 "General Path Index" 42 "General Path Index" 43 "General Path Index" 44 "General Path Index" 45 "General Path Index" 46 "General Path Index" 47 "General Path Index" 48 "General Path Index" 49 "General Path Index" 50 "General Path Index" 51 "General Path Index" 52 "General Path Index" 53 "General Path Index" 54 "General Path Index" 55 "General Path Index" 56 "General Path Index" 57 "General Path Index" 58 "General Path Index" 59 "General Path Index" 60 "General Path Index" 61 "General Path Index" 62 "General Path Index" 63 "General Path Index" ;
VAL_ 524 SEG_Tunnel 0 "Not part of a tunnel" 1 "Part of a tunnel" 2 "Unknown" 3 "Invalid" ;
VAL_ 524 SEG_Bridge 0 "Not part of a bridge" 1 "Part of a bridge" 2 "Unknown" 3 "Invalid" ;
VAL_ 524 SEG_BuiltUpArea 0 "Not part of built-up area" 1 "Part of built-up area" 2 "Unknown" 3 "Invalid" ;
VAL_ 524 SEG_Retransmission 0 "False" 1 "True" ;
VAL_ 524 SEG_Update 0 "False" 1 "True" ;
VAL_ 524 SEG_RelativeProbability 0 "Driving not allowed" 1 "Relative probability" 2 "Relative probability" 3 "Relative probability" 4 "Relative probability" 5 "Relative probability" 6 "Relative probability" 7 "Relative probability" 8 "Relative probability" 9 "Relative probability" 10 "Relative probability" 11 "Relative probability" 12 "Relative probability" 13 "Relative probability" 14 "Relative probability" 15 "Relative probability" 16 "Relative probability" 17 "Relative probability" 18 "Relative probability" 19 "Relative probability" 20 "Relative probability" 21 "Relative probability" 22 "Relative probability" 23 "Relative probability" 24 "Relative probability" 25 "Relative probability" 26 "Relative probability" 27 "Relative probability" 28 "Relative probability" 29 "Relative probability" 30 "Relative probability" 31 "Invalid" ;
VAL_ 524 SEG_FunctionalRoadClass 0 "Unknown" 1 "Freeway" 2 "Arterial(City freeway)" 3 "County" 4 "Collector" 5 "Local" 6 "Etc(ferry unpaved)" 7 "Invalid" ;
VAL_ 524 SEG_CalculatedRoute 0 "Not Calculated Route(MPP)" 1 "Part of Calculated Route" 2 "Off Route or Recalculating" 3 "Invalid" ;
VAL_ 524 SEG_ComplexIntersection 0 "Not part of complex intersection" 1 "Part of of complex intersection" 2 "Unknown" 3 "Invalid" ;
VAL_ 524 SEG_FormOfWay 0 "Unkonwn" 1 "Main road(nondisjunction)" 2 "Main road(disjunction)" 3 "JC" 4 "Plural Junction M" 5 "IC" 6 "Reserved" 7 "Service Area" 8 "Reserved" 9 "Roundabout" 10 "P turn" 11 "U trun" 12 "Pedestrian" 13 "Frontage Road" 14 "Intersection internal" 15 "Invalid" ;
VAL_ 524 SEG_SpeedLimit 0 "Unknown" 1 "Under 5kph(mph)" 2 "7kph(mph)" 3 "10kph(mph)" 4 "15kph(mph)" 5 "20kph(mph)" 6 "25kph(mph)" 7 "30kph(mph)" 8 "35kph(mph)" 9 "40kph(mph)" 10 "45kph(mph)" 11 "50kph(mph)" 12 "55kph(mph)" 13 "60kph(mph)" 14 "65kph(mph)" 15 "70kph(mph)" 16 "75kph(mph)" 17 "80kph(mph)" 18 "85kph(mph)" 19 "90kph(mph)" 20 "95kph(mph)" 21 "100kph(mph)" 22 "105kph(mph)" 23 "110kph(mph)" 24 "115kph(mph)" 25 "120kph(mph)" 26 "130kph(mph)" 27 "140kph(mph)" 28 "150kph(mph)" 29 "160kph(mph)" 30 "Unlimited" 31 "Invalid" ;
VAL_ 524 SEG_SpeedLimitType 0 "Implicit(default)" 1 "Explicit(on traffic sign)" 2 "Explicit(by night)" 3 "Explicit(by day)" 4 "Explicit(time of day)" 5 "Explicit(rain)" 6 "Explicit(snow)" 7 "Unknown" ;
VAL_ 524 SEG_DividedRoad 0 "Not part of a divided road" 1 "Part of a divided road" 2 "Unknown" 3 "Invalid" ;
VAL_ 524 SEG_OppositeLanes 0 "Unknown" 1 "one lane only" 2 "2 or more lanes" 3 "Invalid" ;
VAL_ 524 SEG_DirectionLanes 0 "Unknown" 1 "Lane count" 2 "Lane count" 3 "Lane count" 4 "Lane count" 5 "Lane count" 6 "6 or more lanes" 7 "Invalid" ;
VAL_ 1371 AVM_View 0 "None" 1 "AVM Off" 2 "AVM+Rear View" 3 "AVM+Front View" 4 "RearLeft+Rear View" 5 "FrontLeft+Front View" 6 "RearRight+Rear View" 7 "FrontRight+Front View" 8 "Rear Wide View" 9 "Front Wide View" 10 "Manual Calibration Initial View" 11 "Front Camera Calibration View" 12 "Rear Camera Calibration View" 13 "Left Camera Calibration View" 14 "Right Camera Calibration View" 15 "Direct AVM Video Out View" 16 "Parking Assist Init View" 17 "Parking Assist Rear View" 18 "Parking Assit Front View" 19 "Front 2-Section View" 20 "Reserved" 21 "Reserved" 22 "Reserved" 23 "Driving_RearWide View" 24 "Reserved" 25 "Reserved" 26 "Reserved" 27 "Reserved" 28 "Reserved" 29 "Reserved" 30 "Reserved" 31 "Invalid" ;
VAL_ 1371 AVM_Display_Message 0 "Off" 1 "No Message" 2 "Calibration Mode" 3 "Reserved" 4 "Reserved" 5 "Reserved" 6 "Reserved" 7 "Reserved" 8 "Reserved" 9 "Reserved" 10 "Reserved" 11 "Reserved" 12 "Reserved" 13 "Reserved" 14 "Reserved" 15 "Reserved" 16 "Reserved" 17 "Reserved" 18 "Reserved" 19 "Reserved" 20 "Reserved" 21 "Reserved" 22 "Reserved" 23 "Reserved" 24 "Reserved" 25 "Reserved" 26 "Reserved" 27 "Reserved" 28 "Reserved" 29 "Reserved" 30 "Reserved" 31 "Reserved" 32 "Reserved" 33 "Reserved" 34 "Reserved" 35 "Reserved" 36 "Reserved" 37 "Reserved" 38 "Reserved" 39 "Reserved" 40 "Reserved" 41 "Reserved" 42 "Reserved" 43 "Reserved" 44 "Reserved" 45 "Reserved" 46 "Reserved" 47 "Reserved" 48 "Reserved" 49 "Reserved" 50 "Reserved" 51 "Reserved" 52 "Reserved" 53 "Reserved" 54 "Reserved" 55 "Reserved" 56 "Reserved" 57 "Reserved" 58 "Select ParkingAssist Mode" 59 "Reserved" 60 "Driving_Rear View" 61 "Warning message in AVM" 62 "Warning Front" 63 "Warning Rear" 255 "Invalid" ;
VAL_ 1371 AVM_Option 15 "Invalid" ;
VAL_ 1371 AVM_Btn_Show 0 "Not used" 1 "OFF" 2 "ON" 3 "Invalid" ;
VAL_ 1371 AVM_HU_RearView_Option 0 "None" 1 "AVM+Rear" 2 "RearLeft+Rear" 3 "RearRight+Rear" 4 "Rear Wide" 5 "reserved" 6 "reserved" 7 "reserved" 8 "reserved" 9 "reserved" 10 "reserved" 11 "reserved" 12 "reserved" 13 "reserved" 14 "reserved" 15 "Invalid" ;
VAL_ 1371 AVM_HU_FrontView_Option 0 "None" 1 "AVM+Front" 2 "FrontLeft+Front" 3 "FrontRight+Front" 4 "Front Wide" 5 "Front 2-Section View" 6 "Reserved" 7 "Reserved" 8 "Reserved" 9 "Reserved" 10 "Reserved" 11 "Reserved" 12 "Reserved" 13 "Reserved" 14 "Reserved" 15 "Invalid" ;
VAL_ 1371 AVM_Version 0 "None" 65535 "Invalid" ;
VAL_ 516 POS_MessageType 0 "Reserved" 1 "Position" 2 "Segment" 3 "Stub" 4 "Profile Short" 5 "Profile Long" 6 "Meta Data" 7 "Invalid" ;
VAL_ 516 POS_Offset 8191 "Invalid" ;
VAL_ 516 POS_CyclicCounter 0 "Cyclic Counter" 1 "Cyclic Counter" 2 "Cyclic Counter" 3 "Cyclic Counter" ;
VAL_ 516 POS_PathIndex 0 "Unknown" 1 "Reserved" 2 "Reserved" 3 "Reserved" 4 "Reserved" 5 "Reserved" 6 "Reserved" 7 "Reserved" 8 "General Path Index" 9 "General Path Index" 10 "General Path Index" 11 "General Path Index" 12 "General Path Index" 13 "General Path Index" 14 "General Path Index" 15 "General Path Index" 16 "General Path Index" 17 "General Path Index" 18 "General Path Index" 19 "General Path Index" 20 "General Path Index" 21 "General Path Index" 22 "General Path Index" 23 "General Path Index" 24 "General Path Index" 25 "General Path Index" 26 "General Path Index" 27 "General Path Index" 28 "General Path Index" 29 "General Path Index" 30 "General Path Index" 31 "General Path Index" 32 "General Path Index" 33 "General Path Index" 34 "General Path Index" 35 "General Path Index" 36 "General Path Index" 37 "General Path Index" 38 "General Path Index" 39 "General Path Index" 40 "General Path Index" 41 "General Path Index" 42 "General Path Index" 43 "General Path Index" 44 "General Path Index" 45 "General Path Index" 46 "General Path Index" 47 "General Path Index" 48 "General Path Index" 49 "General Path Index" 50 "General Path Index" 51 "General Path Index" 52 "General Path Index" 53 "General Path Index" 54 "General Path Index" 55 "General Path Index" 56 "General Path Index" 57 "General Path Index" 58 "General Path Index" 59 "General Path Index" 60 "General Path Index" 61 "General Path Index" 62 "General Path Index" 63 "General Path Index" ;
VAL_ 516 POS_PositionIndex 0 "Most probable position" 1 "Second candidate" 2 "Third candidate" 3 "Invalid" ;
VAL_ 516 POS_PositionProbability 0 "Unknown" 1 "Position Probability" 2 "Position Probability" 3 "Position Probability" 4 "Position Probability" 5 "Position Probability" 6 "Position Probability" 7 "Position Probability" 8 "Position Probability" 9 "Position Probability" 10 "Position Probability" 11 "Position Probability" 12 "Position Probability" 13 "Position Probability" 14 "Position Probability" 15 "Position Probability" 16 "Position Probability" 17 "Position Probability" 18 "Position Probability" 19 "Position Probability" 20 "Position Probability" 21 "Position Probability" 22 "Position Probability" 23 "Position Probability" 24 "Position Probability" 25 "Position Probability" 26 "Position Probability" 27 "Position Probability" 28 "Position Probability" 29 "Position Probability" 30 "Position Probability" 31 "Invalid" ;
VAL_ 516 POS_PositionAge 0 "Unknown" 511 "Invalid" ;
VAL_ 516 POS_PositionConfidence 0 "Highest confidence" 1 "Position confidence" 2 "Position confidence" 3 "Position confidence" 4 "Position confidence" 5 "Position confidence" 6 "lowest confidence" 7 "Invalid" ;
VAL_ 516 POS_CurrentLane 0 "Unknown" 1 "Energency lane" 2 "Single lane road" 3 "Left most lane" 4 "Right most lane" 5 "One of middle over three lanes" 6 "Reserved" 7 "Invalid" ;
VAL_ 516 POS_RangeAvgSpeed 510 "Timeout" 511 "Invalid" ;
VAL_ 516 POS_RelativeHeading 0 "In real north direction" 1 "1.417 degrees right" 126 "178.583 degrees right" 127 "Opposite direction" 128 "178.583 degrees left" 253 "1.417 degrees left" 254 "Unknown" 255 "Invalid" ;
VAL_ 532 PROLONG_Value 2147483647 "Invalid" ;
VAL_ 532 PROLONG_MessageType 0 "Reserved" 1 "Position" 2 "Segment" 3 "Stub" 4 "Profile Short" 5 "Profile Long" 6 "Meta Data" 7 "Invalid" ;
VAL_ 532 PROLONG_Offset 8191 "Invalid" ;
VAL_ 532 PROLONG_CyclicCounter 0 "Cyclic Counter" 1 "Cyclic Counter" 2 "Cyclic Counter" 3 "Cyclic Counter" ;
VAL_ 532 PROLONG_PathIndex 0 "Unknown" 1 "Reserved" 2 "Reserved" 3 "Reserved" 4 "Reserved" 5 "Reserved" 6 "Reserved" 7 "Reserved" 8 "General Path Index" 9 "General Path Index" 10 "General Path Index" 11 "General Path Index" 12 "General Path Index" 13 "General Path Index" 14 "General Path Index" 15 "General Path Index" 16 "General Path Index" 17 "General Path Index" 18 "General Path Index" 19 "General Path Index" 20 "General Path Index" 21 "General Path Index" 22 "General Path Index" 23 "General Path Index" 24 "General Path Index" 25 "General Path Index" 26 "General Path Index" 27 "General Path Index" 28 "General Path Index" 29 "General Path Index" 30 "General Path Index" 31 "General Path Index" 32 "General Path Index" 33 "General Path Index" 34 "General Path Index" 35 "General Path Index" 36 "General Path Index" 37 "General Path Index" 38 "General Path Index" 39 "General Path Index" 40 "General Path Index" 41 "General Path Index" 42 "General Path Index" 43 "General Path Index" 44 "General Path Index" 45 "General Path Index" 46 "General Path Index" 47 "General Path Index" 48 "General Path Index" 49 "General Path Index" 50 "General Path Index" 51 "General Path Index" 52 "General Path Index" 53 "General Path Index" 54 "General Path Index" 55 "General Path Index" 56 "General Path Index" 57 "General Path Index" 58 "General Path Index" 59 "General Path Index" 60 "General Path Index" 61 "General Path Index" 62 "General Path Index" 63 "General Path Index" ;
VAL_ 532 PROLONG_ProfileType 0 "Invalid" 1 "Longitude" 2 "Latitude" 3 "Altitude" 4 "Control Point Longitude(Bezier)" 5 "Control Point Latitude(Bezier)" 6 "Control Point Altitude(Bezier)" 7 "Link Identifier" 8 "Traffic Sign" 9 "Reserved for standard type" 10 "Reserved for standard type" 11 "Reserved for standard type" 12 "Reserved for standard type" 13 "Reserved for standard type" 14 "Reserved for standard type" 15 "Reserved for standard type" 16 "Alert Information Spot" 17 "Reserved for system specific types" 18 "Reserved for system specific types" 19 "Reserved for system specific types" 20 "Reserved for system specific types" 21 "Reserved for system specific types" 22 "Reserved for system specific types" 23 "Reserved for system specific types" 24 "Reserved for system specific types" 25 "Reserved for system specific types" 26 "Reserved for system specific types" 27 "Reserved for system specific types" 28 "Reserved for system specific types" 29 "Reserved for system specific types" 30 "Reserved for system specific types" 31 "Reserved for system specific types" ;
VAL_ 532 PROLONG_CountrolPoint 0 "False" 1 "True" ;
VAL_ 532 PROLONG_Retransmission 0 "False" 1 "True" ;
VAL_ 532 PROLONG_Update 0 "False" 1 "True" ;
VAL_ 544 LAT_ACCEL_STAT 0 "Lateral acceleration signal is valid" 1 "Lateral acceleration signal is invalid" ;
VAL_ 544 LAT_ACCEL_DIAG 0 "Lateral acceleration signal is available" 1 "Lateral acceleration signal is not available temporarily" ;
VAL_ 544 LONG_ACCEL_STAT 0 "Longitudinal acceleration signal is valid" 1 "Longitudinal acceleration signal is invalid" ;
VAL_ 544 LONG_ACCEL_DIAG 0 "Longitudinal acceleration signal is available" 1 "Longitudinal acceleration signal is not available temporarily" ;
VAL_ 544 CYL_PRES_STAT 0 "Master cylinder pressure signal is valid" 1 "Master cylinder pressure signal is invalid" ;
VAL_ 544 CYL_PRESS_DIAG 0 "Master cylinder pressure signal is available" 1 "Master cylinder pressure is not available temporarily" ;
VAL_ 544 YAW_RATE_STAT 0 "Yaw rate sensor signal is valid" 1 "Yaw rate sensor signal is invalid" ;
VAL_ 544 YAW_RATE_DIAG 0 "Yaw rate signal is available" 1 "Yaw rate signal is not available temporarily" ;
VAL_ 544 CYL_PRES_FLAG 0 "Off" 1 "On" ;
VAL_ 1369 CF_Gway_MemoryP1Cmd 0 "None" 1 "P1" ;
VAL_ 1369 CF_Gway_MemoryP2Cmd 0 "None" 1 "P2" ;
VAL_ 1369 CF_Gway_PBackP1Cmd 0 "None" 1 "P1" ;
VAL_ 1369 CF_Gway_PBackP2Cmd 0 "None" 1 "P2" ;
VAL_ 1369 CF_Gway_PBackStopCmd 0 "Off" 1 "Stop" ;
VAL_ 1369 CF_Gway_DrvWdwStat 0 "Window Close" 1 "Window Open" ;
VAL_ 1369 CF_Gway_RLWdwState 0 "Window Close" 1 "Window Open" ;
VAL_ 1369 CF_Gway_RRWdwState 0 "Window Close" 1 "Window Open" ;
VAL_ 1369 CF_Gway_AstWdwStat 0 "Window Close" 1 "Window Open" ;
VAL_ 1369 CF_Gway_MemoryEnable 0 "Disable" 1 "Enable" ;
VAL_ 1369 CF_Gway_IMSBuzzer 0 "Off" 1 "On" ;
VAL_ 1369 C_HSWSSysStat 0 "Normal" 1 "System Fail" 2 "Reserved" 3 "Invalid" ;
VAL_ 1369 CF_Gway_WiperSwState 0 "Wiper Sw Off" 1 "Wiper Int or Auto Sw On (Refer to CF_Gway_RainSnsOption)" 2 "Wiper Low Sw On" 3 "Wiper High Sw On" ;
VAL_ 1369 CF_Gway_HCIMSPBackCmd 0 "None" 4095 "Invalid" ;
VAL_ 1369 CF_Gway_DrvSeatBeltIND 0 "Off" 1 "Blinking" 2 "On" ;
VAL_ 1369 CF_Gway_AstSeatBeltIND 0 "Off" 1 "Blinking" 2 "On" ;
VAL_ 1369 CF_Gway_RCSeatBeltIND 0 "Off" 1 "Blinking" 2 "On" ;
VAL_ 1369 CF_Gway_RLSeatBeltIND 0 "Off" 1 "Blinking" 2 "On" ;
VAL_ 1369 CF_Gway_RRSeatBeltIND 0 "Off" 1 "Blinking" 2 "On" ;
VAL_ 1369 CF_Gway_WPCWarning 0 "Off" 1 "Cellphone on the pad" 2 "Charging" 3 "Charging complete" 4 "Cellphone reminder" 5 "Reserved" 6 "Reserved" 7 "Invalid" ;
VAL_ 1369 CF_Gway_SeatBeltWngBuz 0 "Off" 1 "On" ;
VAL_ 520 META_STD_Country_OptADAS 3 "Invalid" 1 "Support Country" 0 "Not Support Country" ;
VAL_ 520 META_MessageType 0 "Reserved" 1 "Position" 2 "Segment" 3 "Stub" 4 "Profile Short" 5 "Profile Long" 6 "Meta Data" 7 "Invalid" ;
VAL_ 520 META_MapProvider 0 "Unknown" 1 "NAVTEQ" 2 "TeleAtlas" 3 "Zenrin" 4 "HMNS" 5 "Reserved" 6 "Reserved" 7 "Invalid" ;
VAL_ 520 META_CountryCode 0 "Unknown" 1023 "Invalid" ;
VAL_ 520 META_CyclicCounter 0 "Cyclic Counter" 1 "Cyclic Counter" 2 "Cyclic Counter" 3 "Cyclic Counter" ;
VAL_ 520 META_MajorProtocolVersion 0 "Major version value" 1 "Major version value" 2 "Major version value" 3 "Major version value" ;
VAL_ 520 META_MinorProtocolSubVer 0 "Minor sub-version value" 1 "Minor sub-version value" 2 "Minor sub-version value" 3 "Minor sub-version value" 4 "Minor sub-version value" 5 "Minor sub-version value" 6 "Minor sub-version value" 7 "Minor sub-version value" ;
VAL_ 520 META_HardwareVersion 0 "Unknown" 511 "Invalid" ;
VAL_ 520 META_DrivingSide 0 "Driving Side Left" 1 "Driving Side Right" ;
VAL_ 520 META_RegionCode 0 "Unknown" 32767 "Invalid" ;
VAL_ 520 META_MapVersionQuarter 0 "Q1" 1 "Q2" 2 "Q3" 3 "Q4" ;
VAL_ 520 META_MapVersionYear 0 "Year" 1 "Year" 2 "Year" 3 "Year" 4 "Year" 5 "Year" 6 "Year" 7 "Year" 8 "Year" 9 "Year" 10 "Year" 11 "Year" 12 "Year" 13 "Year" 14 "Year" 15 "Year" 16 "Year" 17 "Year" 18 "Year" 19 "Year" 20 "Year" 21 "Year" 22 "Year" 23 "Year" 24 "Year" 25 "Year" 26 "Year" 27 "Year" 28 "Year" 29 "Year" 30 "Year" 31 "Year" 32 "Year" 33 "Year" 34 "Year" 35 "Year" 36 "Year" 37 "Year" 38 "Year" 39 "Year" 40 "Year" 41 "Year" 42 "Year" 43 "Year" 44 "Year" 45 "Year" 46 "Year" 47 "Year" 48 "Year" 49 "Year" 50 "Year" 51 "Year" 52 "Year" 53 "Year" 54 "Year" 55 "Year" 56 "Year" 57 "Year" 58 "Year" 59 "Year" 60 "Year" 61 "Year" 62 "Year" 63 "Invalid" ;
VAL_ 520 META_SpeedUnit 0 "Kilometers per hour" 1 "Mile per hour" ;
VAL_ 520 META_MinorProtocolVersion 0 "Minor version value" 1 "Minor version value" 2 "Minor version value" 3 "Minor version value" 4 "Minor version value" 5 "Minor version value" 6 "Minor version value" 7 "Minor version value" 8 "Minor version value" 9 "Minor version value" 10 "Minor version value" 11 "Minor version value" 12 "Minor version value" 13 "Minor version value" 14 "Minor version value" 15 "Minor version value" ;
VAL_ 1363 CF_Gway_ExtTailAct 0 "Off" 1 "On" 3 "B-CAN Time-out" ;
VAL_ 1363 CF_Gway_AutoLightValue 0 "OFF" 1 "Night" ;
VAL_ 1363 CF_Gway_BrakeFluidSw 0 "Off" 1 "On" ;
VAL_ 1363 CF_Gway_AvTail 0 "Off" 1 "On" ;
VAL_ 1363 CF_Gway_RearFogAct 0 "Off" 1 "On" ;
VAL_ 1363 CF_Gway_RRDrSw 0 "Close" 1 "Open" ;
VAL_ 1363 CF_Gway_RLDrSw 0 "Close" 1 "Open" ;
VAL_ 1363 CF_Gway_IntTailAct 0 "Off" 1 "On" ;
VAL_ 1363 CF_Gway_WiperParkPosition 0 "else" 1 "Parking Position" ;
VAL_ 1363 CF_Gway_ESCLNotLockedWarn 0 "Off" 1 "On" ;
VAL_ 1363 CF_Gway_IDoutWarn 0 "Off" 1 "On" ;
VAL_ 1363 CF_Gway_ImmoLp 0 "Off" 1 "On" ;
VAL_ 1363 CF_Gway_VehicleNotPWarn 0 "Off" 1 "On" ;
VAL_ 1363 CF_Gway_DeactivationWarn 0 "Off" 1 "On" ;
VAL_ 1363 CF_Gway_KeyBATDischargeWarn 0 "Off" 1 "On" ;
VAL_ 1363 CF_Gway_SJBDeliveryMode 0 "Before Delivery(Welcome Off)" 1 "After Delivery(Welcome On)" ;
VAL_ 1363 CF_Gway_SMKDispWarn 0 "Off" 1 "Shift_P_Warning" 2 "Key_Bat_Discharge_Warning" 3 "Not_Unlocked_Warning" 4 "AC_Plug_Connected_Warning(EV/PHEV)" 5 "Escl_Ecu_Fail_Warning" 6 "Engine_Start_Operation_IND" 7 "Auth_Fail_Warning" 8 "Key_Removal_IND" 9 "SMK_Lamp_Warning" 10 "SSB_Warning" 11 "Auth_Fail_Warning2" 12 "Vehicle_Not_P_Warning" 13 "Stop Lamp Fuse Fail Warning" 14 "Not P_N Warning" ;
VAL_ 1363 CF_Gway_WngBuz 0 "Off" 1 "SeatBelt Warning" 2 "Key Operated Warning" 3 "Parking Brake Warning" 4 "Sun Roof Open Warning" 5 "Key Learning Sound(NoSMKOption)" 6 "ICE Warning" 7 "Rear Fog Warning" ;
VAL_ 1479 SCR_LEVEL_WARN_LAMP 0 "Lamp Off" 1 "Lamp On" ;
VAL_ 1479 SCR_LEVEL_WARN 0 "No display" 1 "'urea level low' or 'AdBlue low' or 'reagent low'" 2 "¡®fill up urea¡¯ or ¡®fill up AdBlue¡¯ or ¡®fill up reagent' (Buzzer Optional)" 3 "¡®fill up urea¡¯ or ¡®fill up AdBlue¡¯ or ¡®fill up reagent' AND No Restart In %Mileage% (Buzzer Optional)" 4 "¡®Urea Level Empty'" ;
VAL_ 1479 SCR_SYS_ERROR_WARN 0 "No display" 1 "¡®incorrect urea detected¡¯ or ¡®incorrect AdBlue detected¡¯ or ¡®incorrect reagent detected" 2 "urea dosing malfunction¡¯ or ¡®AdBlue dosing malfunction¡¯ or ¡®reagent dosing malfunction" 3 "¡®urea dosing interruption¡¯, ¡®AdBlue dosing interruption¡¯, or ¡®reagent dosing interruption'" 4 "'emissions too high-check urea', 'emissions too high-check AdBlue', 'emissions too high-check" ;
VAL_ 1479 SCR_INDUCEMENT_EXIT_COND 0 "No display" 1 "'fill up correct urea' AND No Restart In %Mileage%" 2 "¡®check the SCR system' AND No Restart In %Mileage%" ;
VAL_ 1479 SCR_UREA_LEVEL 255 "urea level sensor error" ;
VAL_ 1479 SCR_REMAINING_DISTANCE 0 "No display" 65535 "Error" ;
VAL_ 1348 NAVI_ISLWMapSource 7 "Invalid" 6 "Reserved" 5 "Reserved" 4 "Reserved" 3 "Reserved" 2 "Server Data (TOMTOM, MCP, TPEG)" 1 "Embedded Map (HERE, HMNS)" 0 "None" ;
VAL_ 1348 Navi_ISLW_CountryCode 1023 "Invalid" 0 "Unknown" ;
VAL_ 1348 Navi_ISLW_LinkClass 7 "Invalid" 6 "RoundAbout" 5 "Aterial_Country" 4 "Restarea" 3 "JC" 2 "IC" 1 "Freeway" 0 "Unknown" ;
VAL_ 1348 Navi_ISLW_SpdUnit 3 "Invalid" 2 "MPH" 1 "KPH" 0 "None" ;
VAL_ 1348 Navi_ISLW_Frwinfo 7 "Invalid" 4 "Restarea" 3 "Branch" 2 "Exit" 1 "Entrance" 0 "None" ;
VAL_ 1348 Navi_ISLW_SpdLimit 255 "Invalid" 254 "Unlimited" 0 "None" ;
VAL_ 1348 HU_AliveStatus 0 "Not Ready" 1 "On Mode" 2 "Head Unit Update Mode" 3 "Invalid" ;
VAL_ 809 CONF_TCU 14 "AMT vehicle" 9 "E-CLUTCH vehicle" 0 "A/T vehicle (Step Shift A/T)" 10 "CVT vehicle (CVT A/T)" 11 "DCT vehicle (DCT A/T)" 15 "M/T vehicle" ;
VAL_ 809 MUL_CODE 0 "CAN_VERS" 1 "CONF_TCU" 2 "OBD_FRF_ACK" 3 "TQ_STND" ;
VAL_ 809 ACC_ACT 0 "Auto cruise control is not active" 1 "Auto cruise control is active" ;
VAL_ 809 BRAKE_ACT 0 "EMS does not support this function." 1 "Brake switch is not pressed (OFF)" 2 "Brake switch is pressed (ON)" 3 "Brake switch failure" ;
VAL_ 809 ENG_CHR 0 "Fuel - Gasoline,  ETC - No" 1 "Fuel - LPI(LPG),  ETC - No" 2 "Fuel - Diesel,     ETC - No" 3 "Reserved" 4 "Fuel - Gasoline,  ETC - Applied" 5 "Fuel - LPI(LPG),  ETC - Applied" 6 "Fuel - Diesel,    ETC - Applied" 7 "GDI type engine" ;
VAL_ 809 TPS 32 "Idle (port value is learnt)" 245 "Throttle perpendicular" 255 "Throttle defective" ;
VAL_ 809 PV_AV_CAN 0 "Accelerator Pedal not activated" 254 "Accelerator Pedal fully activated" 255 "Accelerator Pedal is defective (fail state) orNon-ETC system (APS is not installed)" ;
VAL_ 1345 CF_Gway_IGNSw 0 "Key Off" 1 "Key In" 2 "ACC" 3 "IGN" 4 "Start" 7 "B-CAN signal Time-out" ;
VAL_ 1345 CF_Gway_RKECmd 0 "None" 1 "Lock" 2 "Unlock" 3 "Panic" 4 "Panic Stop" 5 "Trunk(Or Tail Gate)" 6 "Reserved" 7 "Reserved" ;
VAL_ 1345 CF_Gway_DrvDrSw 0 "Close" 1 "Open" 3 "B-CAN signal Time-out" ;
VAL_ 1345 CF_Gway_DrvSeatBeltSw 0 "Unbelted" 1 "Belted" 3 "B-CAN signal Time-out" ;
VAL_ 1345 CF_Gway_TrunkTgSw 0 "Trunk Close" 1 "Trunk Open" 3 "B-CAN Time-out" ;
VAL_ 1345 CF_Gway_SMKOption 0 "Non SMK Option" 1 "SMK Option" ;
VAL_ 1345 CF_Gway_HoodSw 0 "Hood Close" 1 "Hood Open" 3 "B-CAN signal Time-out" ;
VAL_ 1345 CF_Gway_TurnSigLh 0 "Off" 1 "On" 3 "B-CAN Time-out" ;
VAL_ 1345 CF_Gway_WiperIntT 0 "Step1(SLOW)" 1 "Step2" 2 "Step3" 3 "Step4" 4 "Step5(FAST)" ;
VAL_ 1345 CF_Gway_WiperIntSw 0 "Off" 1 "On" ;
VAL_ 1345 CF_Gway_WiperLowSw 0 "Off" 1 "On" ;
VAL_ 1345 CF_Gway_WiperHighSw 0 "Off" 1 "On" ;
VAL_ 1345 CF_Gway_WiperAutoSw 0 "Off" 1 "On" ;
VAL_ 1345 CF_Gway_HeadLampLow 0 "Off" 1 "On" ;
VAL_ 1345 CF_Gway_HeadLampHigh 0 "Off" 1 "On" ;
VAL_ 1345 CF_Gway_HazardSw 0 "Off" 1 "On" 3 "B-CAN signal Time-out" ;
VAL_ 1345 CF_Gway_AstDrSw 0 "Close" 1 "Open" ;
VAL_ 1345 CF_Gway_LightSwState 0 "Light Sw Off" 1 "Tail Sw On" 2 "HeadLamp Low Sw On" 3 "AutoLight Sw On or DRL Sw On (USA, Non-Autolight)" ;
VAL_ 1345 CF_Gway_TSigRHSw 0 "Off" 1 "On" ;
VAL_ 1345 CF_Gway_TSigLHSw 0 "Off" 1 "On" ;
VAL_ 1345 CF_Gway_DriveTypeOption 0 "LHD" 1 "RHD" ;
VAL_ 1345 CF_Gway_PassiveAccessLock 0 "None" 1 "Lock" 2 "PassiveTrunkLock" ;
VAL_ 1345 CF_Gway_PassiveAccessUnlock 0 "None" 1 "UnLock" 2 "Unlock only DRV Door" 3 "PIC_Key_Reminder" ;
VAL_ 1345 CF_Gway_PassingSW 0 "SW Off" 1 "SW On" ;
VAL_ 1345 CF_Gway_HBAControlMode 0 "HLamp High Control Mode by BCM" 1 "HLamp High Control Mode by HBA" ;
VAL_ 1345 CF_Gway_InhibitRMT 0 "Gear_R Switch Off" 1 "Gear_R Switch On" 3 "B-CAN signal Time-out" ;
VAL_ 1345 CF_Gway_RainSnsOption 0 "Non Rain Sensor Option" 1 "Rain Sensor Option" ;
VAL_ 1345 C_SunRoofOpenState 0 "close" 1 "open" ;
VAL_ 1345 CF_Gway_ParkBrakeSw 0 "Off" 1 "On" 3 "B-CAN Time-out" ;
VAL_ 1345 CF_Gway_TurnSigRh 0 "Off" 1 "On" 3 "B-CAN Time-out" ;
VAL_ 1407 HU_Type 16 "AVN(Tuner DVD KOR)" 17 "AVN(Tuner DVD EUR)" 18 "AVN(Tuner DVD China)" 19 "AVN(Tuner DVD Japan)" 20 "AVN(Tuner DVD EUR)" 21 "AVN(Tuner CDP KOR)" 22 "AVN(Tuner CDP EUR)" 23 "AVN(Tuner CDP China)" 24 "AVN(Tuner CDP Japan)" 25 "AVN(Tuner CDP EUR)" 32 "AVNT (Open)" 33 "AVNT (Not open)" 48 "Economic Audio" 64 "Standard Audio (3.0 below)" 80 "AV(Tuner DVD KOR)" 81 "AV(Tuner DVD EUR)" 82 "AV(Tuner DVD China)" 83 "AV(Tuner DVD Japan)" 84 "AV(Tuner DVD EUR)" 85 "AV(Tuner CDP KOR)" 86 "AV(Tuner CDP EUR)" 87 "AV(Tuner CDP China)" 88 "AV(Tuner CDP Japan)" 89 "AV(Tuner CDP EUR)" 96 "VIT Basic AVN" 97 "VIT Premier AVN" 255 "Invalid" 98 "EU AVN 2.0" 99 "Super Premium w Navi" 100 "Super Premium w_o Navi" 101 "Premium w Navi" 102 "Premium w_o Navi" 103 "Display Audio" 65 "Standard Audio 4.0" 112 "Compact AVN" ;
VAL_ 1407 HU_DistributeInfo 255 "Invalid" 1 "KOREA" 2 "NORTH AMERICA" 3 "CANADA" 4 "EAST EUROPE" 5 "WEST EUROPE" 6 "CHINA" 7 "INDIA" 8 "AUSTRALIA" 9 "MIDDLE EAST" 10 "AFRICA" 11 "SOUTH AMERICA" 12 "RESERVED" 13 "RESERVED" 14 "GENERAL" 15 "RESERVED" ;
VAL_ 1407 HU_AdasSupport 0 "Not Support" 1 "ADAS Support(General Map)" 2 "ADAS Support(Precise Map)" 3 "Reserved" 4 "Reserved" 5 "Reserved" 6 "Reserved" 7 "Invalid" ;
VAL_ 1397 HU_AVM_Cal_Cmd 0 "Off" 1 "Update" 2 "Re-enter" 3 "Enter" 4 "Finish" 5 "Front Cal" 6 "Rear Cal" 7 "Left Cal" 8 "Right Cal" 9 "reserved" 10 "reserved" 11 "reserved" 12 "reserved" 13 "reserved" 14 "reserved" 15 "Invalid" ;
VAL_ 1397 HU_AVM_PT_X 4095 "Invalid x-coordinate" ;
VAL_ 1397 HU_AVM_PT_Y 4095 "Invalid y-coordinate" ;
VAL_ 1397 HU_AVM_SelectedMenu 0 "Off" 1 "AVM+Rear View" 31 "Invalid" 2 "AVM+Front View" 3 "RearLeft+Rear View" 4 "FrontLeft+Front View" 5 "RearRight+Rear View" 6 "FrontRight+Front View" 7 "Rear Wide View" 8 "Front Wide View" 9 "Front 2-section View" 10 "Driving Rear View" 11 "Reserved" 12 "Reserved" 13 "Reserved" 14 "Reserved" 15 "Reserved" 16 "Reserved" 17 "Reserved" 18 "Reserved" 19 "Reserved" 20 "Reserved" 21 "Reserved" 22 "Reserved" 23 "Reserved" 24 "Reserved" 25 "Reserved" 26 "Reserved" 27 "Reserved" 28 "Reserved" 29 "Reserved" 30 "Reserved" ;
VAL_ 1397 HU_AVM_CameraOff 0 "Default" 1 "Camera Off" 2 "Not Used" 3 "Invalid" ;
VAL_ 1397 HU_AVM_Option 15 "Invalid" ;
VAL_ 1397 HU_AVM_RearView_Option 0 "None" 1 "AVM+Rear" 2 "RearLeft+Rear" 3 "RearRight+Rear" 4 "Rear Wide" 5 "reserved" 6 "reserved" 7 "reserved" 8 "reserved" 9 "reserved" 10 "reserved" 11 "reserved" 12 "reserved" 13 "reserved" 14 "reserved" 15 "Invalid" ;
VAL_ 1397 HU_AVM_FrontView_Option 0 "None" 1 "AVM+Front" 2 "FrontLeft+Front" 3 "FrontRight+Front" 4 "Front Wide" 5 "Front 2-section View" 6 "Reserved" 7 "Reserved" 8 "Reserved" 9 "Reserved" 10 "Reserved" 11 "Reserved" 12 "Reserved" 13 "Reserved" 14 "Reserved" 15 "Invalid" ;
SIG_GROUP_ 1183 NAVI_ISLW2 1 : Navi_ISLW_TunnelExist Navi_ISLW_TimeSpd Navi_ISLW_WeatherInfo Navi_ISLW_BUAInfo Navi_ISLW_TollExist;
SIG_GROUP_ 1260 LKA13 1 : ISLA_AddtnlSign ISLA_SchoolZone ISLA_Cntry ISLA_Popup ISLA_AutoUsmSta ISLA_OffstUsmSta CF_ISLW_Spd_Dis_NAVI_Con2 CF_ISLW_Spd_Dis_NAVI_Con1 CF_ISLW_Spd_Dis_CLU_Con2 CF_ISLW_Spd_Dis_CLU_Con1 CF_ISLW_ConInfo_Sta_Con2 CF_ISLW_ConInfo_Sta_Con1 ISLA_OptUsmSta;
SIG_GROUP_ 1155 FCA12 1 : FCA_USM FCA_DrvSetState FCA_WarningTargetDisplay;
SIG_GROUP_ 1190 CLU19 1 : CF_AVN_WarningTimingNValueSet CF_AVN_FCANValueSet;
SIG_GROUP_ 550 NAVI_STD_STUB_E 1 : STUB_DirectionLanes STUB_OppositeLanes STUB_RightOfWay STUB_LastStubAtOffset STUB_TurnAngle STUB_FormOfWay STUB_ComplexIntersection STUB_CalculatedRoute STUB_FunctionalRoadClass STUB_RelativeProbability STUB_Update STUB_Retransmission STUB_SubPathIndex STUB_PathIndex STUB_CyclicCounter STUB_Offset STUB_MessageType;
SIG_GROUP_ 528 NAVI_STD_PROSHORT_E 1 : PROSHORT_Update PROSHORT_Retransmission PROSHORT_ControlPoint PROSHORT_ProfileType PROSHORT_Value1 PROSHORT_Value0 PROSHORT_Distance PROSHORT_Accuracy PROSHORT_PathIndex PROSHORT_CyclicCounter PROSHORT_Offset PROSHORT_MessageType;
SIG_GROUP_ 524 NAVI_STD_SEG_E 1 : SEG_DirectionLanes SEG_OppositeLanes SEG_DividedRoad SEG_SpeedLimitType SEG_SpeedLimit SEG_FormOfWay SEG_ComplexIntersection SEG_CalculatedRoute SEG_FunctionalRoadClass SEG_RelativeProbability SEG_Update SEG_Retransmission SEG_BuiltUpArea SEG_Bridge SEG_Tunnel SEG_PathIndex SEG_CyclicCounter SEG_Offset SEG_MessageType;
SIG_GROUP_ 516 NAVI_STD_POS_E 1 : POS_RelativeHeading POS_RangeAvgSpeed POS_CurrentLane POS_PositionConfidence POS_PositionAge POS_PositionProbability POS_PositionIndex POS_PathIndex POS_CyclicCounter POS_Offset POS_MessageType;
SIG_GROUP_ 532 NAVI_STD_PROLONG_E 1 : PROLONG_Update PROLONG_Retransmission PROLONG_CountrolPoint PROLONG_ProfileType PROLONG_PathIndex PROLONG_CyclicCounter PROLONG_Offset PROLONG_MessageType PROLONG_Value;
SIG_GROUP_ 544 ESP12 1 : ESP12_AliveCounter ESP12_Checksum CYL_PRES_FLAG CYL_PRESS_DIAG CYL_PRES_STAT CYL_PRES YAW_RATE YAW_RATE_STAT YAW_RATE_DIAG LAT_ACCEL_STAT LAT_ACCEL_DIAG LONG_ACCEL LONG_ACCEL_STAT LAT_ACCEL LONG_ACCEL_DIAG;
SIG_GROUP_ 520 NAVI_STD_META_E 1 : META_STD_Country_OptADAS META_MinorProtocolVersion META_SpeedUnit META_MapVersionYear META_MapVersionQuarter META_RegionCode META_DrivingSide META_HardwareVersion META_MinorProtocolSubVer META_MajorProtocolVersion META_CyclicCounter META_CountryCode META_MapProvider META_MessageType;
SIG_GROUP_ 1363 CGW2 1 : CF_Gway_WiperParkPosition;
SIG_GROUP_ 1348 NAVI_ISLW 1 : NAVI_ISLWMapSource Navi_ISLW_CountryCode Navi_ISLW_LinkClass Navi_ISLW_SpdUnit Navi_ISLW_Frwinfo Navi_ISLW_SpdLimit HU_AliveStatus;
SIG_GROUP_ 809 EMS12 1 : PV_AV_CAN;
SIG_GROUP_ 688 SAS11_FS 1 : MsgCount CheckSum SAS_Stat SAS_Speed SAS_Angle;
SIG_GROUP_ 1345 CGW1 1 : CF_Gway_ParkBrakeSw C_SunRoofOpenState CF_Gway_RainSnsOption CF_Gway_InhibitRMT CF_Gway_PassiveAccessUnlock CF_Gway_PassiveAccessLock CF_Gway_DriveTypeOption CF_Gway_AstDrSw CF_Gway_WiperHighSw CF_Gway_WiperLowSw CF_Gway_WiperIntSw CF_Gway_WiperIntT CF_Gway_HoodSw CF_Gway_SMKOption CF_Gway_TrunkTgSw CF_Gway_DrvSeatBeltSw CF_Gway_DrvDrSw CF_Gway_RKECmd CF_Gway_HBAControlMode CF_Gway_PassingSW CF_Gway_WiperAutoSw CF_Gway_HeadLampLow CF_Gway_HeadLampHigh CF_Gway_HazardSw CF_Gway_LightSwState CF_Gway_IGNSw CF_Gway_TurnSigLh CF_Gway_TurnSigRh CF_Gway_TSigRHSw CF_Gway_TSigLHSw;
SIG_GROUP_ 1407 HU_MON_PE_01 1 : HU_AdasSupport HU_DistributeInfo HU_Type;
